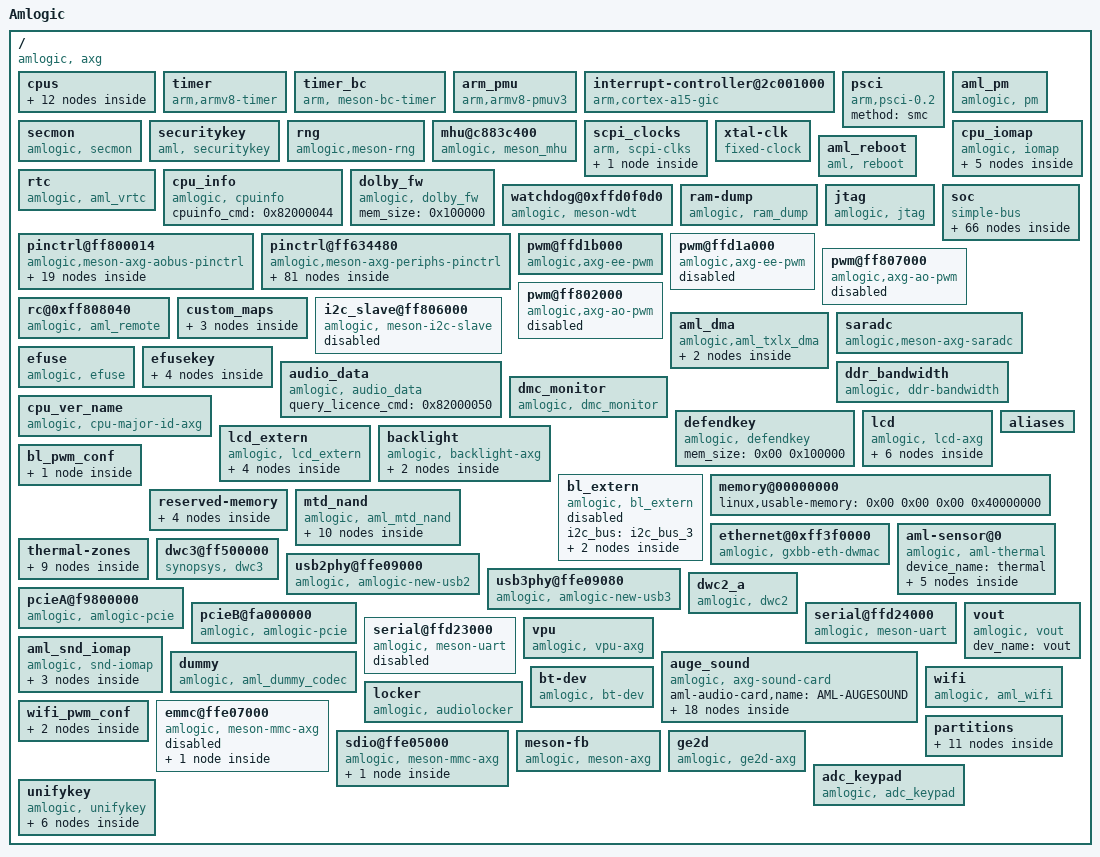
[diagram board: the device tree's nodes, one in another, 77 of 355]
/dts-v1/;

/ {
	model = "Amlogic";
	amlogic-dt-id = "axg_s400_1g";
	compatible = "amlogic, axg";
	interrupt-parent = <0x01>;
	#address-cells = <0x02>;
	#size-cells = <0x02>;

	cpus {
		#address-cells = <0x02>;
		#size-cells = <0x00>;
		phandle = <0x63>;

		cpu-map {

			cluster0 {
				phandle = <0x64>;

				core0 {
					cpu = <0x02>;
				};

				core1 {
					cpu = <0x03>;
				};

				core2 {
					cpu = <0x04>;
				};

				core3 {
					cpu = <0x05>;
				};
			};
		};

		cpu@0 {
			device_type = "cpu";
			compatible = "arm,cortex-a53\0arm,armv8";
			reg = <0x00 0x00>;
			enable-method = "psci";
			clocks = <0x06 0x00>;
			clock-names = "cpu-cluster.0";
			cpu-idle-states = <0x07>;
			phandle = <0x02>;
		};

		cpu@1 {
			device_type = "cpu";
			compatible = "arm,cortex-a53\0arm,armv8";
			reg = <0x00 0x01>;
			enable-method = "psci";
			clocks = <0x06 0x00>;
			clock-names = "cpu-cluster.0";
			cpu-idle-states = <0x07>;
			phandle = <0x03>;
		};

		cpu@2 {
			device_type = "cpu";
			compatible = "arm,cortex-a53\0arm,armv8";
			reg = <0x00 0x02>;
			enable-method = "psci";
			clocks = <0x06 0x00>;
			clock-names = "cpu-cluster.0";
			cpu-idle-states = <0x07>;
			phandle = <0x04>;
		};

		cpu@3 {
			device_type = "cpu";
			compatible = "arm,cortex-a53\0arm,armv8";
			reg = <0x00 0x03>;
			enable-method = "psci";
			clocks = <0x06 0x00>;
			clock-names = "cpu-cluster.0";
			cpu-idle-states = <0x07>;
			phandle = <0x05>;
		};

		idle-states {
			entry-method = "arm,psci-0.2";

			cpu-sleep-0 {
				compatible = "arm,idle-state";
				arm,psci-suspend-param = <0x10000>;
				local-timer-stop;
				entry-latency-us = <0x1388>;
				exit-latency-us = <0x1388>;
				min-residency-us = <0x3a98>;
				phandle = <0x07>;
			};
		};
	};

	timer {
		compatible = "arm,armv8-timer";
		interrupts = <0x01 0x0d 0xff08 0x01 0x0e 0xff08 0x01 0x0b 0xff08 0x01 0x0a 0xff08>;
	};

	timer_bc {
		compatible = "arm, meson-bc-timer";
		reg = <0x00 0xffd0f190 0x00 0x04 0x00 0xffd0f194 0x00 0x04>;
		timer_name = "Meson TimerF";
		clockevent-rating = <0x12c>;
		clockevent-shift = <0x14>;
		clockevent-features = <0x23>;
		interrupts = <0x00 0x3c 0x01>;
		bit_enable = <0x10>;
		bit_mode = <0x0c>;
		bit_resolution = <0x00>;
	};

	arm_pmu {
		compatible = "arm,armv8-pmuv3";
		interrupts = <0x00 0x89 0x04>;
		reg = <0x00 0xff634680 0x00 0x04>;
		cpumasks = <0x0f>;
		relax-timer-ns = <0x989680>;
		max-wait-cnt = <0x2710>;
	};

	interrupt-controller@2c001000 {
		compatible = "arm,cortex-a15-gic\0arm,cortex-a9-gic";
		#interrupt-cells = <0x03>;
		#address-cells = <0x00>;
		interrupt-controller;
		reg = <0x00 0xffc01000 0x00 0x1000 0x00 0xffc02000 0x00 0x100>;
		interrupts = <0x01 0x09 0xf04>;
		phandle = <0x01>;
	};

	psci {
		compatible = "arm,psci-0.2";
		method = "smc";
	};

	aml_pm {
		compatible = "amlogic, pm";
		device_name = "aml_pm";
		status = "okay";
		debug_reg = <0xff8000a8>;
		exit_reg = <0xff80023c>;
	};

	secmon {
		compatible = "amlogic, secmon";
		memory-region = <0x08>;
		in_base_func = <0x82000020>;
		out_base_func = <0x82000021>;
		reserve_mem_size = <0x300000>;
	};

	securitykey {
		compatible = "aml, securitykey";
		storage_query = <0x82000060>;
		storage_read = <0x82000061>;
		storage_write = <0x82000062>;
		storage_tell = <0x82000063>;
		storage_verify = <0x82000064>;
		storage_status = <0x82000065>;
		storage_list = <0x82000067>;
		storage_remove = <0x82000068>;
		storage_in_func = <0x82000023>;
		storage_out_func = <0x82000024>;
		storage_block_func = <0x82000025>;
		storage_size_func = <0x82000027>;
		storage_set_enctype = <0x8200006a>;
		storage_get_enctype = <0x8200006b>;
		storage_version = <0x8200006c>;
	};

	rng {
		compatible = "amlogic,meson-rng";
		status = "okay";
		#address-cells = <0x02>;
		#size-cells = <0x02>;
		reg = <0x00 0xff634018 0x00 0x04>;
		quality = [03 e8];
	};

	mhu@c883c400 {
		compatible = "amlogic, meson_mhu";
		reg = <0x00 0xff63c400 0x00 0x4c 0x00 0xfffd3000 0x00 0x800>;
		interrupts = <0x00 0xd1 0x01 0x00 0xd2 0x01>;
		#mbox-cells = <0x01>;
		mbox-names = "cpu_to_scp_low\0cpu_to_scp_high";
		mboxes = <0x09 0x00 0x09 0x01>;
		phandle = <0x09>;
	};

	scpi_clocks {
		compatible = "arm, scpi-clks";

		scpi_clocks@0 {
			compatible = "arm, scpi-clk-indexed";
			#clock-cells = <0x01>;
			clock-indices = <0x00>;
			clock-output-names = "vcpu";
			phandle = <0x06>;
		};
	};

	cpu_iomap {
		compatible = "amlogic, iomap";
		#address-cells = <0x02>;
		#size-cells = <0x02>;
		ranges;

		io_cbus_base {
			reg = <0x00 0xffd00000 0x00 0x100000>;
		};

		io_apb_base {
			reg = <0x00 0xffe00000 0x00 0x100000>;
		};

		io_aobus_base {
			reg = <0x00 0xff800000 0x00 0x100000>;
		};

		io_vapb_base {
			reg = <0x00 0xff900000 0x00 0x50000>;
		};

		io_hiu_base {
			reg = <0x00 0xff63c000 0x00 0x10000>;
		};
	};

	xtal-clk {
		compatible = "fixed-clock";
		clock-frequency = <0x16e3600>;
		clock-output-names = "xtal";
		#clock-cells = <0x00>;
		phandle = <0x0a>;
	};

	rtc {
		compatible = "amlogic, aml_vrtc";
		alarm_reg_addr = <0xff8000a8>;
		timer_e_addr = <0xffd0f188>;
		init_date = "2015/01/01";
		status = "okay";
	};

	cpu_info {
		compatible = "amlogic, cpuinfo";
		status = "okay";
		cpuinfo_cmd = <0x82000044>;
	};

	aml_reboot {
		compatible = "aml, reboot";
		sys_reset = <0x84000009>;
		sys_poweroff = <0x84000008>;
	};

	dolby_fw {
		compatible = "amlogic, dolby_fw";
		mem_size = <0x100000>;
		status = "okay";
		phandle = <0x65>;
	};

	watchdog@0xffd0f0d0 {
		compatible = "amlogic, meson-wdt";
		status = "okay";
		default_timeout = <0x0a>;
		reset_watchdog_method = <0x01>;
		reset_watchdog_time = <0x02>;
		shutdown_timeout = <0x0a>;
		firmware_timeout = <0x06>;
		suspend_timeout = <0x06>;
		reg = <0x00 0xffd0f0d0 0x00 0x10>;
		clock-names = "xtal";
		clocks = <0x0a>;
		phandle = <0x66>;
	};

	ram-dump {
		compatible = "amlogic, ram_dump";
		status = "okay";
		reg = <0x00 0xff6345e0 0x00 0x04>;
		reg-names = "PREG_STICKY_REG8";
		store_device = "data";
	};

	jtag {
		compatible = "amlogic, jtag";
		status = "okay";
		select = "disable";
		pinctrl-names = "jtag_apao_pins\0jtag_apee_pins";
		pinctrl-0 = <0x0b>;
		pinctrl-1 = <0x0c>;
	};

	pinctrl@ff800014 {
		compatible = "amlogic,meson-axg-aobus-pinctrl";
		#address-cells = <0x02>;
		#size-cells = <0x02>;
		ranges;
		phandle = <0x67>;

		ao-bank@ff800014 {
			reg = <0x00 0xff800014 0x00 0x08 0x00 0xff80002c 0x00 0x04 0x00 0xff800024 0x00 0x08>;
			reg-names = "mux\0pull\0gpio";
			gpio-controller;
			#gpio-cells = <0x02>;
			phandle = <0x0f>;
		};

		remote_pin {
			phandle = <0x21>;

			mux {
				groups = "remote_input_ao";
				function = "remote_input_ao";
			};
		};

		irblaster_pin {
			phandle = <0x11>;

			mux {
				groups = "remote_out_ao";
				function = "remote_out_ao";
			};
		};

		ao_uart {
			phandle = <0x12>;

			mux {
				groups = "uart_ao_tx_a\0uart_ao_rx_a";
				function = "uart_ao_a";
			};
		};

		ao_b_1_uart {
			phandle = <0x68>;

			mux {
				groups = "uart_ao_tx_b\0uart_ao_rx_b";
				function = "uart_ao_b";
			};
		};

		ao_i2c {
			phandle = <0x69>;

			mux {
				groups = "i2c_ao_sck_4\0i2c_ao_sda_5";
				function = "i2c_ao";
			};
		};

		ao_i2c_pin1 {
			phandle = <0x6a>;

			mux {
				groups = "i2c_ao_sck_8\0i2c_ao_sda_9";
				function = "i2c_ao";
			};
		};

		ao_i2c_pin2 {
			phandle = <0x10>;

			mux {
				groups = "i2c_ao_sck_10\0i2c_ao_sda_11";
				function = "i2c_ao";
			};
		};

		s_i2c {
			phandle = <0x26>;

			mux {
				groups = "i2c_ao_slave_sck\0i2c_ao_slave_sda";
				function = "i2c_ao_slave";
			};
		};

		jtag_apao_pin {
			phandle = <0x0b>;

			mux {
				groups = "jtag_ao_tdi\0jtag_ao_tdo\0jtag_ao_clk\0jtag_ao_tms";
				function = "jtag_ao";
			};
		};
	};

	pinctrl@ff634480 {
		compatible = "amlogic,meson-axg-periphs-pinctrl";
		#address-cells = <0x02>;
		#size-cells = <0x02>;
		ranges;
		phandle = <0x6b>;

		banks@ff634480 {
			reg = <0x00 0xff634480 0x00 0x40 0x00 0xff6344e8 0x00 0x14 0x00 0xff634520 0x00 0x14 0x00 0xff634430 0x00 0x3c>;
			reg-names = "mux\0pull\0pull-enable\0gpio";
			gpio-controller;
			#gpio-cells = <0x02>;
			phandle = <0x2c>;
		};

		external_eth_pins {
			phandle = <0x36>;

			mux {
				groups = "eth_mdio_y\0eth_mdc_y\0eth_rgmii_rx_clk_y\0eth_rx_dv_y\0eth_rxd0_y\0eth_rxd1_y\0eth_rxd2_rgmii\0eth_rxd3_rgmii\0eth_rgmii_tx_clk\0eth_txen_y\0eth_txd0_y\0eth_txd1_y\0eth_txd2_rgmii\0eth_txd3_rgmii";
				function = "eth";
			};
		};

		ao_b_uart {
			phandle = <0x13>;

			mux {
				groups = "uart_ao_tx_b_z\0uart_ao_rx_b_z";
				function = "uart_ao_b";
			};
		};

		a_uart {
			phandle = <0x3d>;

			mux {
				groups = "uart_tx_a\0uart_rx_a\0uart_cts_a\0uart_rts_a";
				function = "uart_a";
			};
		};

		b_uart {
			phandle = <0x3e>;

			mux {
				groups = "uart_tx_b_z\0uart_rx_b_z";
				function = "uart_b";
			};
		};

		a_i2c {
			phandle = <0x6c>;

			mux {
				groups = "i2c0_sck\0i2c0_sda";
				function = "i2c0";
			};
		};

		b_i2c {
			phandle = <0x0e>;

			mux {
				groups = "i2c1_sck_z\0i2c1_sda_z";
				function = "i2c1";
			};
		};

		b_i2c_pin1 {
			phandle = <0x6d>;

			mux {
				groups = "i2c1_sck_x\0i2c1_sda_x";
				function = "i2c1";
			};
		};

		c_i2c {
			phandle = <0x6e>;

			mux {
				groups = "i2c2_sck_x\0i2c2_sda_x";
				function = "i2c2";
			};
		};

		c_i2c_pin1 {
			phandle = <0x6f>;

			mux {
				groups = "i2c2_sck_a\0i2c2_sda_a";
				function = "i2c2";
			};
		};

		d_i2c {
			phandle = <0x70>;

			mux {
				groups = "i2c3_sda_a6\0i2c3_sck_a7";
				function = "i2c3";
			};
		};

		d_i2c_pin1 {
			phandle = <0x71>;

			mux {
				groups = "i2c3_sda_a12\0i2c3_sck_a13";
				function = "i2c3";
			};
		};

		d_i2c_pin2 {
			phandle = <0x72>;

			mux {
				groups = "i2c3_sda_a19\0i2c3_sck_a20";
				function = "i2c3";
			};
		};

		spi0 {
			phandle = <0x73>;

			mux {
				groups = "spi0_clk\0spi0_mosi\0spi0_miso";
				function = "spi0";
			};
		};

		spi1_a {
			phandle = <0x74>;

			mux {
				groups = "spi1_clk_a\0spi1_mosi_a\0spi1_miso_a";
				function = "spi1";
			};
		};

		spi1_x {
			phandle = <0x75>;

			mux {
				groups = "spi1_clk_x\0spi1_mosi_x\0spi1_miso_x";
				function = "spi1";
			};
		};

		nand_pulldown {
			phandle = <0x76>;

			mux {
				groups = "emmc_nand_d0\0emmc_nand_d1\0emmc_nand_d2\0emmc_nand_d3\0emmc_nand_d4\0emmc_nand_d5\0emmc_nand_d6\0emmc_nand_d7";
				function = "nand";
				bias-pull-down;
			};
		};

		nand_pullup {
			phandle = <0x77>;

			mux {
				groups = "nand_ce0";
				function = "nand";
				bias-pull-up;
			};
		};

		all_nand_pins {
			phandle = <0x31>;

			mux {
				groups = "emmc_nand_d0\0emmc_nand_d1\0emmc_nand_d2\0emmc_nand_d3\0emmc_nand_d4\0emmc_nand_d5\0emmc_nand_d6\0emmc_nand_d7\0nand_ce0\0nand_ale\0nand_cle\0nand_wen_clk\0nand_ren_wr";
				function = "nand";
				input-enable;
			};
		};

		nand_cs {
			phandle = <0x32>;

			mux {
				groups = "nand_ce0";
				function = "nand";
			};
		};

		emmc_clk_cmd_pins {
			phandle = <0x4b>;

			mux {
				groups = "emmc_clk\0emmc_cmd";
				function = "emmc";
				input-enable;
				bias-pull-up;
			};
		};

		emmc_conf_pull_up {
			phandle = <0x4c>;

			mux {
				groups = "emmc_nand_d0\0emmc_nand_d1\0emmc_nand_d2\0emmc_nand_d3\0emmc_nand_d4\0emmc_nand_d5\0emmc_nand_d6\0emmc_nand_d7\0emmc_clk\0emmc_cmd";
				function = "emmc";
				input-enable;
				bias-pull-up;
			};
		};

		emmc_conf_pull_done {
			phandle = <0x4d>;

			mux {
				groups = "emmc_ds";
				function = "emmc";
				input-enable;
				bias-pull-down;
			};
		};

		sdio_clk_cmd_pins {
			phandle = <0x4e>;

			mux {
				groups = "sdio_clk\0sdio_cmd";
				function = "sdio";
				input-enable;
				bias-pull-up;
			};
		};

		sdio_all_pins {
			phandle = <0x4f>;

			mux {
				groups = "sdio_d0\0sdio_d1\0sdio_d2\0sdio_d3\0sdio_clk\0sdio_cmd";
				function = "sdio";
				input-enable;
				bias-pull-up;
			};
		};

		wifi_32k_pins {
			phandle = <0x49>;

			mux {
				groups = "pwm_a_x20";
				function = "pwm_a";
			};
		};

		jtag_apee_pin {
			phandle = <0x0c>;

			mux {
				groups = "jtag_tdo_x\0jtag_tdi_x\0jtag_clk_x\0jtag_tms_x";
				function = "jtag_ee";
			};
		};

		tdmout_a {
			phandle = <0x15>;

			mux {
				groups = "tdma_sclk\0tdma_fs";
				function = "tdma_out";
			};
		};

		tdmout_a_data {
			phandle = <0x17>;

			mux {
				groups = "tdma_dout1_x15";
				function = "tdma_out";
			};
		};

		tdmin_a {
			phandle = <0x16>;

			mux {
				groups = "tdma_din0";
				function = "tdma_in";
			};
		};

		tdmb_mclk {
			phandle = <0x18>;

			mux {
				groups = "mclk_b";
				function = "mclk_b";
			};
		};

		tdmout_b {
			phandle = <0x19>;

			mux {
				groups = "tdmb_sclk\0tdmb_fs";
				function = "tdmb_out";
			};
		};

		tdmin_b {
			phandle = <0x1a>;

			mux {
				groups = "tdmb_din0\0tdmb_din1\0tdmb_din2_a12\0tdmb_din3_a13";
				function = "tdmb_in";
			};
		};

		tdmc_mclk {
			phandle = <0x1b>;

			mux {
				groups = "mclk_a";
				function = "mclk_a";
			};
		};

		tdmout_c {
			phandle = <0x1c>;

			mux {
				groups = "tdmc_sclk\0tdmc_fs\0tdmc_dout0\0tdmc_dout2_a6\0tdmc_dout3_a7";
				function = "tdmc_out";
			};
		};

		tdmin_c {
			phandle = <0x1d>;

			mux {
				groups = "tdmc_din1";
				function = "tdmc_in";
			};
		};

		spidfout {
			phandle = <0x1e>;

			mux {
				groups = "spdif_out_a20";
				function = "spdif_out";
			};
		};

		spidfin {
			phandle = <0x1f>;

			mux {
				groups = "spdif_in_a19";
				function = "spdif_in";
			};
		};

		pdmin {
			phandle = <0x20>;

			mux {
				groups = "pdm_dclk_a14\0pdm_din0\0pdm_din1\0pdm_din2\0pdm_din3";
				function = "pdm";
			};
		};

		bl_pwm_on_pin {
			phandle = <0x2d>;

			mux {
				groups = "pwm_b_z";
				function = "pwm_b";
			};
		};

		bl_pwm_off_pin {
			phandle = <0x2e>;

			mux {
				pins = "GPIOZ_4";
				function = "gpio_periphs";
				output-high;
			};
		};
	};

	soc {
		compatible = "simple-bus";
		#address-cells = <0x02>;
		#size-cells = <0x02>;
		ranges;

		cbus@ffd00000 {
			compatible = "simple-bus";
			reg = <0x00 0xffd00000 0x00 0x25000>;
			#address-cells = <0x02>;
			#size-cells = <0x02>;
			ranges = <0x00 0x00 0x00 0xffd00000 0x00 0x25000>;
			phandle = <0x78>;

			interrupt-controller@f080 {
				compatible = "amlogic,meson-gpio-intc\0amlogic,meson-axg-gpio-intc";
				reg = <0x00 0xf080 0x00 0x10>;
				interrupt-controller;
				#interrupt-cells = <0x02>;
				amlogic,channel-interrupts = <0x40 0x41 0x42 0x43 0x44 0x45 0x46 0x47>;
				status = "okay";
				phandle = <0x79>;
			};

			meson_clk_msr {
				compatible = "amlogic, gxl_measure";
				reg = <0x00 0x18004 0x00 0x04 0x00 0x1800c 0x00 0x04>;
			};

			i2c@1f000 {
				compatible = "amlogic,meson-axg-i2c";
				status = "disabled";
				reg = <0x00 0x1f000 0x00 0x20>;
				interrupts = <0x00 0x15 0x01 0x00 0x2f 0x01>;
				#address-cells = <0x01>;
				#size-cells = <0x00>;
				clocks = <0x0d 0x27>;
				clock-names = "clk_i2c";
				clock-frequency = <0x186a0>;
				phandle = <0x7a>;
			};

			i2c@1e000 {
				compatible = "amlogic,meson-axg-i2c";
				status = "okay";
				reg = <0x00 0x1e000 0x00 0x20>;
				interrupts = <0x00 0xd6 0x01 0x00 0x30 0x01>;
				#address-cells = <0x01>;
				#size-cells = <0x00>;
				clocks = <0x0d 0x27>;
				clock-names = "clk_i2c";
				clock-frequency = <0x186a0>;
				pinctrl-names = "default";
				pinctrl-0 = <0x0e>;
				phandle = <0x7b>;

				tlv320adc3101_32@32 {
					compatible = "ti,tlv320adc3101";
					#sound-dai-cells = <0x00>;
					reg = <0x19>;
					differential_pair = <0x01>;
					status = "okay";
					phandle = <0x42>;
				};

				tas5707_36@36 {
					compatible = "ti,tas5707";
					#sound-dai-cells = <0x00>;
					reg = <0x1b>;
					status = "okay";
					reset_pin = <0x0f 0x04 0x00>;
					phandle = <0x44>;
				};

				tas5707_3a@3a {
					compatible = "ti,tas5707";
					#sound-dai-cells = <0x00>;
					reg = <0x1d>;
					status = "okay";
					phandle = <0x45>;
				};
			};

			i2c@1d000 {
				compatible = "amlogic,meson-axg-i2c";
				status = "disabled";
				reg = <0x00 0x1d000 0x00 0x20>;
				interrupts = <0x00 0xd7 0x01 0x00 0x31 0x01>;
				#address-cells = <0x01>;
				#size-cells = <0x00>;
				clocks = <0x0d 0x27>;
				clock-names = "clk_i2c";
				clock-frequency = <0x186a0>;
				phandle = <0x7c>;
			};

			i2c@1c000 {
				compatible = "amlogic,meson-axg-i2c";
				status = "disabled";
				reg = <0x00 0x1c000 0x00 0x20>;
				interrupts = <0x00 0x27 0x01 0x00 0x32 0x01>;
				#address-cells = <0x01>;
				#size-cells = <0x00>;
				clocks = <0x0d 0x27>;
				clock-names = "clk_i2c";
				clock-frequency = <0x186a0>;
				phandle = <0x7d>;
			};

			spi@13000 {
				compatible = "amlogic,meson-axg-spicc";
				reg = <0x00 0x13000 0x00 0x40>;
				interrupts = <0x00 0x51 0x04>;
				clocks = <0x0d 0x26 0x0d 0x76>;
				clock-names = "core\0comp";
				#address-cells = <0x01>;
				#size-cells = <0x00>;
				status = "disabled";
				phandle = <0x7e>;
			};

			spi@15000 {
				compatible = "amlogic,meson-axg-spicc";
				reg = <0x00 0x15000 0x00 0x40>;
				interrupts = <0x00 0x52 0x04>;
				clocks = <0x0d 0x2b 0x0d 0x76>;
				clock-names = "core\0comp";
				#address-cells = <0x01>;
				#size-cells = <0x00>;
				status = "disabled";
				phandle = <0x7f>;
			};
		};

		aobus@ff800000 {
			compatible = "simple-bus";
			reg = <0x00 0xff800000 0x00 0xa000>;
			#address-cells = <0x02>;
			#size-cells = <0x02>;
			ranges = <0x00 0x00 0x00 0xff800000 0x00 0xa000>;
			phandle = <0x80>;

			cpu_version {
				reg = <0x00 0x220 0x00 0x04>;
			};

			clock-controller@0 {
				compatible = "amlogic,axg-aoclkc";
				#clock-cells = <0x01>;
				reg = <0x00 0x00 0x00 0x320>;
				phandle = <0x81>;
			};

			i2c@5000 {
				compatible = "amlogic,meson-axg-i2c";
				status = "okay";
				reg = <0x00 0x5000 0x00 0x20>;
				interrupts = <0x00 0xc3 0x01>;
				#address-cells = <0x01>;
				#size-cells = <0x00>;
				clocks = <0x0d 0x27>;
				clock-names = "clk_i2c";
				clock-frequency = <0x186a0>;
				pinctrl-names = "default";
				pinctrl-0 = <0x10>;
				phandle = <0x82>;

				aml_pca9557@0x1f {
					compatible = "aml, ledring";
					reg = <0x1f>;
					mode = <0x00>;
					key_num = <0x04>;
					led_dev_name = "aml_ledring";
					key_dev_name = "aml_pca_key";
					key_name = "mute\0pause\0vol+\0vol-";
					key_value = <0xc8 0xc9 0xca 0xcb>;
					status = "okay";
					phandle = <0x83>;
				};

				tlv320adc3101_30@30 {
					compatible = "ti,tlv320adc3101";
					#sound-dai-cells = <0x00>;
					reg = <0x18>;
					status = "disable";
					phandle = <0x84>;
				};

				tlv320adc3101_34@30 {
					compatible = "ti,tlv320adc3101";
					#sound-dai-cells = <0x00>;
					reg = <0x1a>;
					status = "disable";
					phandle = <0x85>;
				};

				tlv320adc3101_36@30 {
					compatible = "ti,tlv320adc3101";
					#sound-dai-cells = <0x00>;
					reg = <0x1b>;
					status = "disable";
					phandle = <0x86>;
				};

				es7243_10@10 {
					compatible = "MicArray_0";
					#sound-dai-cells = <0x00>;
					reg = <0x10>;
					status = "disable";
					phandle = <0x87>;
				};

				es7243_12@12 {
					compatible = "MicArray_1";
					#sound-dai-cells = <0x00>;
					reg = <0x12>;
					status = "disable";
					phandle = <0x88>;
				};

				es7243_13@13 {
					compatible = "MicArray_2";
					#sound-dai-cells = <0x00>;
					reg = <0x13>;
					status = "disable";
					phandle = <0x89>;
				};

				is31f3236a@0x78 {
					compatible = "issi,is31fl3236";
					reg = <0x3c>;
					status = "disable";
					phandle = <0x8a>;

					led1_r {
						label = "LED1_R";
						reg_offset = <0x18>;
					};

					led1_g {
						label = "LED1_G";
						reg_offset = <0x17>;
					};

					led1_b {
						label = "LED1_B";
						reg_offset = <0x16>;
					};

					led2_r {
						label = "LED2_R";
						reg_offset = <0x15>;
					};

					led2_g {
						label = "LED2_G";
						reg_offset = <0x14>;
					};

					led2_b {
						label = "LED2_B";
						reg_offset = <0x13>;
					};

					led3_r {
						label = "LED3_R";
						reg_offset = <0x12>;
					};

					led3_g {
						label = "LED3_G";
						reg_offset = <0x11>;
					};

					led3_b {
						label = "LED3_B";
						reg_offset = <0x10>;
					};

					led4_r {
						label = "LED4_R";
						reg_offset = <0x0f>;
					};

					led4_g {
						label = "LED4_G";
						reg_offset = <0x0e>;
					};

					led4_b {
						label = "LED4_B";
						reg_offset = <0x0d>;
					};

					led5_r {
						label = "LED5_R";
						reg_offset = <0x24>;
					};

					led5_g {
						label = "LED5_G";
						reg_offset = <0x23>;
					};

					led5_b {
						label = "LED5_B";
						reg_offset = <0x22>;
					};

					led6_r {
						label = "LED6_R";
						reg_offset = <0x21>;
					};

					led6_g {
						label = "LED6_G";
						reg_offset = <0x20>;
					};

					led6_b {
						label = "LED6_B";
						reg_offset = <0x1f>;
					};

					led7_r {
						label = "LED7_R";
						reg_offset = <0x1e>;
					};

					led7_g {
						label = "LED7_G";
						reg_offset = <0x1d>;
					};

					led7_b {
						label = "LED7_B";
						reg_offset = <0x1c>;
					};

					led8_r {
						label = "LED8_R";
						reg_offset = <0x1b>;
					};

					led8_g {
						label = "LED8_G";
						reg_offset = <0x1a>;
					};

					led8_b {
						label = "LED8_B";
						reg_offset = <0x19>;
					};
				};
			};

			meson-irblaster@c0 {
				compatible = "amlogic, aml_irblaster";
				reg = <0x00 0xc0 0x00 0x0c 0x00 0x40 0x00 0x04>;
				#irblaster-cells = <0x02>;
				pinctrl-names = "default";
				pinctrl-0 = <0x11>;
				status = "disabled";
				phandle = <0x8b>;
			};

			serial@3000 {
				compatible = "amlogic, meson-uart";
				reg = <0x00 0x3000 0x00 0x18>;
				interrupts = <0x00 0xc1 0x01>;
				status = "okay";
				clocks = <0x0a>;
				clock-names = "clk_uart";
				xtal_tick_en = <0x01>;
				fifosize = <0x40>;
				pinctrl-names = "default";
				pinctrl-0 = <0x12>;
				support-sysrq = <0x00>;
				phandle = <0x8c>;
			};

			serial@4000 {
				compatible = "amlogic, meson-uart";
				reg = <0x00 0x4000 0x00 0x18>;
				interrupts = <0x00 0xc5 0x01>;
				status = "disable";
				clocks = <0x0a>;
				clock-names = "clk_uart";
				fifosize = <0x40>;
				pinctrl-names = "default";
				pinctrl-0 = <0x13>;
				phandle = <0x8d>;
			};
		};

		periphs@ff634400 {
			compatible = "simple-bus";
			reg = <0x00 0xff634400 0x00 0x1c00>;
			#address-cells = <0x02>;
			#size-cells = <0x02>;
			ranges = <0x00 0x00 0x00 0xff634400 0x00 0x1c00>;
			phandle = <0x8e>;
		};

		hiubus@ff63c000 {
			compatible = "simple-bus";
			reg = <0x00 0xff63c000 0x00 0x10000>;
			#address-cells = <0x02>;
			#size-cells = <0x02>;
			ranges = <0x00 0x00 0x00 0xff63c000 0x00 0x10000>;
			phandle = <0x8f>;

			clock-controller@0 {
				compatible = "amlogic,axg-clkc";
				#clock-cells = <0x01>;
				reg = <0x00 0x00 0x00 0x320>;
				phandle = <0x0d>;
			};
		};

		audiobus@0xff642000 {
			compatible = "amlogic, audio-controller\0simple-bus";
			reg = <0x00 0xff642000 0x00 0x2000>;
			#address-cells = <0x02>;
			#size-cells = <0x02>;
			ranges = <0x00 0x00 0x00 0xff642000 0x00 0x2000>;
			phandle = <0x90>;

			audio_clocks {
				compatible = "amlogic, axg-audio-clocks";
				#clock-cells = <0x01>;
				reg = <0x00 0x00 0x00 0xb0>;
				phandle = <0x14>;
			};

			ddr_manager {
				compatible = "amlogic, axg-audio-ddr-manager";
				interrupts = <0x00 0x54 0x01 0x00 0x55 0x01 0x00 0x56 0x01 0x00 0x58 0x01 0x00 0x59 0x01 0x00 0x5a 0x01>;
				interrupt-names = "toddr_a\0toddr_b\0toddr_c\0frddr_a\0frddr_b\0frddr_c";
			};

			tdma {
				compatible = "amlogic, axg-snd-tdma";
				#sound-dai-cells = <0x00>;
				dai-tdm-lane-slot-mask-in = <0x01 0x00>;
				dai-tdm-lane-slot-mask-out = <0x00 0x01>;
				dai-tdm-clk-sel = <0x00>;
				clocks = <0x14 0x14 0x0d 0x0c>;
				clock-names = "mclk\0clk_srcpll";
				pinctrl-names = "tdm_pins";
				pinctrl-0 = <0x15 0x16 0x17>;
				phandle = <0x3f>;
			};

			tdmb {
				compatible = "amlogic, axg-snd-tdmb";
				#sound-dai-cells = <0x00>;
				dai-tdm-lane-slot-mask-in = <0x01 0x01 0x01 0x01>;
				dai-tdm-clk-sel = <0x01>;
				clocks = <0x14 0x15 0x0d 0x0d>;
				clock-names = "mclk\0clk_srcpll";
				pinctrl-names = "tdm_pins";
				pinctrl-0 = <0x18 0x19 0x1a>;
				phandle = <0x41>;
			};

			tdmc {
				compatible = "amlogic, axg-snd-tdmc";
				#sound-dai-cells = <0x00>;
				dai-tdm-lane-slot-mask-in = <0x00 0x01 0x00 0x00>;
				dai-tdm-lane-slot-mask-out = <0x01 0x00 0x01 0x01>;
				#dai-tdm-lane-oe-slot-mask-in = <0x00 0x00 0x00 0x00>;
				#dai-tdm-lane-oe-slot-mask-out = <0x01 0x00 0x00 0x00>;
				dai-tdm-clk-sel = <0x02>;
				clocks = <0x14 0x16 0x0d 0x0e>;
				clock-names = "mclk\0clk_srcpll";
				pinctrl-names = "tdm_pins";
				pinctrl-0 = <0x1b 0x1c 0x1d>;
				phandle = <0x43>;
			};

			tdm@3 {
				compatible = "amlogic, axg-snd-tdmlb";
				#sound-dai-cells = <0x00>;
				dai-tdm-lane-lb-slot-mask-in = <0x01 0x00 0x00 0x00>;
				dai-tdm-clk-sel = <0x01>;
				clocks = <0x14 0x15 0x0d 0x0d>;
				clock-names = "mclk\0clk_srcpll";
				lb-src-sel = <0x01>;
				status = "disabled";
				phandle = <0x91>;
			};

			spdif {
				compatible = "amlogic, axg-snd-spdif";
				#sound-dai-cells = <0x00>;
				clocks = <0x0d 0x0c 0x0d 0x04 0x14 0x10 0x14 0x11 0x14 0x1a 0x14 0x1b>;
				clock-names = "sysclk\0fixed_clk\0gate_spdifin\0gate_spdifout\0clk_spdifin\0clk_spdifout";
				interrupts = <0x00 0x57 0x01>;
				interrupt-names = "irq_spdifin";
				pinctrl-names = "spdif_pins";
				pinctrl-0 = <0x1e 0x1f>;
				auto_asrc = <0x00>;
				status = "okay";
				phandle = <0x47>;
			};

			pdm {
				compatible = "amlogic, axg-snd-pdm";
				#sound-dai-cells = <0x00>;
				clocks = <0x14 0x01 0x0d 0x03 0x0d 0x0f 0x14 0x1c 0x14 0x1d>;
				clock-names = "gate\0sysclk_srcpll\0dclk_srcpll\0pdm_dclk\0pdm_sysclk";
				pinctrl-names = "pdm_pins";
				pinctrl-0 = <0x20>;
				filter_mode = <0x01>;
				status = "okay";
				phandle = <0x46>;
			};

			loopback@0 {
				compatible = "amlogic, axg-loopback";
				#sound-dai-cells = <0x00>;
				clocks = <0x14 0x01 0x0d 0x03 0x0d 0x0f 0x14 0x1c 0x14 0x1d 0x0d 0x0c 0x14 0x14>;
				clock-names = "pdm_gate\0pdm_sysclk_srcpll\0pdm_dclk_srcpll\0pdm_dclk\0pdm_sysclk\0tdminlb_mpll\0tdminlb_mclk";
				datain_src = <0x04>;
				datain_chnum = <0x06>;
				datain_chmask = <0x3f>;
				datain-lane-mask-in = <0x01 0x01 0x01 0x00>;
				mclk-fs = <0x100>;
				datalb_src = <0x02>;
				datalb_chnum = <0x02>;
				datalb_chmask = <0x03>;
				datalb-lane-mask-in = <0x01 0x00 0x00 0x00>;
				status = "okay";
				phandle = <0x48>;
			};

			resample {
				compatible = "amlogic, axg-resample";
				clocks = <0x0d 0x0f 0x14 0x19 0x14 0x20>;
				clock-names = "resample_pll\0resample_src\0resample_clk";
				resample_module = <0x03>;
				status = "okay";
				phandle = <0x92>;
			};

			pwrdet {
				compatible = "amlogic, axg-power-detect";
				interrupts = <0x00 0x5b 0x01>;
				interrupt-names = "pwrdet_irq";
				pwrdet_src = <0x04>;
				hi_th = <0x70000>;
				lo_th = <0x16000>;
				status = "disabled";
				phandle = <0x93>;
			};
		};
	};

	pwm@ffd1b000 {
		compatible = "amlogic,axg-ee-pwm";
		reg = <0x00 0xffd1b000 0x00 0x20>;
		#pwm-cells = <0x03>;
		clocks = <0x0a 0x0a 0x0a 0x0a>;
		clock-names = "clkin0\0clkin1\0clkin2\0clkin3";
		status = "okay";
		phandle = <0x30>;
	};

	pwm@ffd1a000 {
		compatible = "amlogic,axg-ee-pwm";
		reg = <0x00 0xffd1a000 0x00 0x20>;
		#pwm-cells = <0x03>;
		clocks = <0x0a 0x0a 0x0a 0x0a>;
		clock-names = "clkin0\0clkin1\0clkin2\0clkin3";
		status = "disabled";
		phandle = <0x94>;
	};

	pwm@ff807000 {
		compatible = "amlogic,axg-ao-pwm";
		reg = <0x00 0xff807000 0x00 0x20>;
		#pwm-cells = <0x03>;
		clocks = <0x0a 0x0a 0x0a 0x0a>;
		clock-names = "clkin0\0clkin1\0clkin2\0clkin3";
		status = "disabled";
		phandle = <0x95>;
	};

	pwm@ff802000 {
		compatible = "amlogic,axg-ao-pwm";
		reg = <0x00 0xff802000 0x00 0x20>;
		#pwm-cells = <0x03>;
		clocks = <0x0a 0x0a 0x0a 0x0a>;
		clock-names = "clkin0\0clkin1\0clkin2\0clkin3";
		status = "disabled";
		phandle = <0x96>;
	};

	rc@0xff808040 {
		compatible = "amlogic, aml_remote";
		dev_name = "meson-remote";
		reg = <0x00 0xff808040 0x00 0x44 0x00 0xff808000 0x00 0x20>;
		status = "okay";
		protocol = <0x01>;
		interrupts = <0x00 0xc4 0x01>;
		pinctrl-names = "default";
		pinctrl-0 = <0x21>;
		map = <0x22>;
		max_frame_time = <0xc8>;
		phandle = <0x97>;
	};

	custom_maps {
		mapnum = <0x03>;
		map0 = <0x23>;
		map1 = <0x24>;
		map2 = <0x25>;
		phandle = <0x22>;

		map_0 {
			mapname = "amlogic-remote-1";
			customcode = <0xfb04>;
			release_delay = <0x50>;
			size = <0x32>;
			keymap = <0x47000b 0x130002 0x100003 0x110004 0xf0005 0xc0006 0xd0007 0xb0008 0x80009 0x9000a 0x5c0061 0x51003d 0x50003e 0x40003f 0x4d0040 0x430041 0x170042 0x43 0x10044 0x160057 0x49000e 0x60082 0x140083 0x440067 0x1d006c 0x1c0069 0x48006a 0x53007d 0x450068 0x19006d 0x520077 0x5007a 0x59007b 0x1b0078 0x40079 0x1a0074 0xa000f 0xe0071 0x1f0066 0x1e0084 0x70085 0x120086 0x540087 0x20088 0x4f001e 0x420030 0x5d002e 0x4c0020 0x580089 0x55008c>;
			phandle = <0x23>;
		};

		map_1 {
			mapname = "amlogic-remote-2";
			customcode = <0xfe01>;
			release_delay = <0x50>;
			size = <0x35>;
			keymap = <0x10002 0x20003 0x30004 0x40005 0x50006 0x60007 0x70008 0x80009 0x9000a 0xa000b 0x1f01d2 0x15008b 0x16000f 0xc0192 0xd0193 0xe0073 0xf0072 0x110066 0x1c006a 0x1b0069 0x190067 0x1a006c 0x1d001c 0x170071 0x4900db 0x43009e 0x1201d5 0x1401d6 0x1801d7 0x590166 0x5a00a6 0x100074 0x4200a5 0x4400a3 0x1e00a8 0x4b00d0 0x5800a4 0x460082 0x400083 0x380046 0x5701d0 0x5b01d1 0x54018e 0x4c018f 0x4e0190 0x550191 0x5300ed 0x5200ee 0x3900d4 0x4100d5 0xb00d6 0xd8 0x1300d9>;
			phandle = <0x24>;
		};

		map_2 {
			mapname = "amlogic-remote-3";
			customcode = <0xbd02>;
			release_delay = <0x50>;
			size = <0x11>;
			keymap = <0xca0067 0xd2006c 0x990069 0xc1006a 0xce0061 0x450074 0xc50085 0x800071 0xd0000f 0xd6007d 0x950066 0xdd0068 0x8c006d 0x890083 0x9c0082 0x9a0078 0xcd0079>;
			phandle = <0x25>;
		};
	};

	i2c_slave@ff806000 {
		compatible = "amlogic, meson-i2c-slave";
		status = "disabled";
		reg = <0x00 0xff806000 0x00 0x20>;
		interrupts = <0x00 0xc2 0x01>;
		pinctrl-names = "default";
		pinctrl-0 = <0x26>;
		phandle = <0x98>;
	};

	aml_dma {
		compatible = "amlogic,aml_txlx_dma";
		reg = <0x00 0xff63e000 0x00 0x48>;
		interrupts = <0x00 0xb4 0x01>;

		aml_aes {
			compatible = "amlogic,aes_dma";
			dev_name = "aml_aes_dma";
			status = "okay";
		};

		aml_sha {
			compatible = "amlogic,sha_dma";
			dev_name = "aml_sha_dma";
			status = "okay";
		};
	};

	saradc {
		compatible = "amlogic,meson-axg-saradc";
		status = "okay";
		#io-channel-cells = <0x01>;
		clocks = <0x0a 0x0d 0x7a>;
		clock-names = "xtal\0saradc_clk";
		interrupts = <0x00 0x49 0x01>;
		reg = <0x00 0xff809000 0x00 0x38>;
		phandle = <0x5c>;
	};

	efuse {
		compatible = "amlogic, efuse";
		read_cmd = <0x82000030>;
		write_cmd = <0x82000031>;
		get_max_cmd = <0x82000033>;
		key = <0x27>;
		clocks = <0x0d 0x3d>;
		clock-names = "efuse_clk";
		status = "ok";
		phandle = <0x99>;
	};

	efusekey {
		keynum = <0x04>;
		key0 = <0x28>;
		key1 = <0x29>;
		key2 = <0x2a>;
		key3 = <0x2b>;
		phandle = <0x27>;

		key_0 {
			keyname = "mac";
			offset = <0x00>;
			size = <0x06>;
			phandle = <0x28>;
		};

		key_1 {
			keyname = "mac_bt";
			offset = <0x06>;
			size = <0x06>;
			phandle = <0x29>;
		};

		key_2 {
			keyname = "mac_wifi";
			offset = <0x0c>;
			size = <0x06>;
			phandle = <0x2a>;
		};

		key_3 {
			keyname = "usid";
			offset = <0x12>;
			size = <0x10>;
			phandle = <0x2b>;
		};
	};

	audio_data {
		compatible = "amlogic, audio_data";
		query_licence_cmd = <0x82000050>;
		status = "okay";
		phandle = <0x9a>;
	};

	ddr_bandwidth {
		compatible = "amlogic, ddr-bandwidth";
		status = "okay";
		reg = <0x00 0xff638000 0x00 0x100 0x00 0xff637000 0x00 0x100>;
		interrupts = <0x00 0x34 0x01>;
		interrupt-names = "ddr_bandwidth";
	};

	dmc_monitor {
		compatible = "amlogic, dmc_monitor";
		status = "okay";
		reg_base = <0xff638800>;
		interrupts = <0x00 0x33 0x01>;
	};

	cpu_ver_name {
		compatible = "amlogic, cpu-major-id-axg";
	};

	defendkey {
		compatible = "amlogic, defendkey";
		mem_size = <0x00 0x100000>;
		status = "okay";
		phandle = <0x9b>;
	};

	lcd {
		compatible = "amlogic, lcd-axg";
		mode = "tablet";
		status = "okay";
		key_valid = <0x00>;
		clocks = <0x0d 0x22 0x0d 0x2a 0x0d 0x72 0x0d 0x1e 0x0d 0x1f>;
		clock-names = "dsi_host_gate\0dsi_phy_gate\0dsi_meas\0mipi_enable_gate\0mipi_bandgap_gate";
		reg = <0x00 0xffd06000 0x00 0x400 0x00 0xff640000 0x00 0x100>;
		interrupts = <0x00 0x03 0x01>;
		interrupt-names = "vsync";
		pinctrl_version = <0x01>;
		lcd_cpu-gpios = <0x2c 0x06 0x00>;
		lcd_cpu_gpio_names = "GPIOZ_6";

		lcd_0 {
			model_name = "B080XAN01";
			interface = "mipi";
			basic_setting = <0x300 0x400 0x3b4 0x474 0x08 0x77 0x9f>;
			lcd_timing = <0x40 0x38 0x00 0x32 0x1e 0x00>;
			clk_attr = <0x00 0x00 0x01 0x3dd6dc0>;
			mipi_attr = <0x04 0x226 0x00 0x01 0x00 0x02 0x01 0x00>;
			dsi_init_on = <0x05 0x01 0x11 0xfd 0x01 0x14 0x05 0x01 0x29 0xfd 0x01 0x14 0xff 0x00>;
			dsi_init_off = <0x05 0x01 0x28 0xfd 0x01 0x0a 0x05 0x01 0x10 0xfd 0x01 0x0a 0xff 0x00>;
			extern_init = <0xff>;
			power_on_step = <0x00 0x00 0x00 0x0a 0x00 0x00 0x01 0x14 0x02 0x00 0x00 0x00 0xff 0x00 0x00 0x00>;
			power_off_step = <0x02 0x00 0x00 0x32 0x00 0x00 0x00 0x64 0xff 0x00 0x00 0x00>;
			backlight_index = <0x00>;
		};

		lcd_1 {
			model_name = "TV070WSM";
			interface = "mipi";
			basic_setting = <0x258 0x400 0x2a8 0x410 0x08 0x5f 0xa3>;
			lcd_timing = <0x18 0x24 0x00 0x02 0x08 0x00>;
			clk_attr = <0x00 0x00 0x01 0x286f900>;
			mipi_attr = <0x04 0x15e 0x00 0x01 0x00 0x02 0x00 0x00>;
			dsi_init_on = <0xf0 0x03 0x00 0x01 0x1e 0xf0 0x03 0x00 0x00 0x0a 0xf0 0x03 0x00 0x01 0x1e 0xff 0x00>;
			dsi_init_off = <0xff 0x00>;
			extern_init = <0x01>;
			power_on_step = <0x00 0x00 0x00 0x14 0x02 0x00 0x00 0x00 0xff 0x00 0x00 0x00>;
			power_off_step = <0x02 0x00 0x00 0x64 0x00 0x00 0x00 0x64 0xff 0x00 0x00 0x00>;
			backlight_index = <0x00>;
		};

		lcd_2 {
			model_name = "P070ACB";
			interface = "mipi";
			basic_setting = <0x258 0x400 0x2a8 0x4aa 0x08 0x03 0x05>;
			lcd_timing = <0x18 0x24 0x00 0x0a 0x50 0x00>;
			clk_attr = <0x00 0x00 0x01 0x2e755c0>;
			mipi_attr = <0x04 0x190 0x00 0x01 0x00 0x02 0x00 0x00>;
			dsi_init_on = <0xff 0x00>;
			dsi_init_off = <0xff 0x00>;
			extern_init = <0x03>;
			power_on_step = <0x00 0x00 0x01 0x14 0x00 0x00 0x00 0x0a 0x00 0x00 0x01 0x14 0x02 0x00 0x00 0x00 0xff 0x00 0x00 0x00>;
			power_off_step = <0x02 0x00 0x00 0x32 0x00 0x00 0x00 0x64 0xff 0x00 0x00 0x00>;
			backlight_index = <0x00>;
		};

		lcd_3 {
			model_name = "ST7701";
			interface = "mipi";
			basic_setting = <0x1e0 0x356 0x23a 0x3a1 0x08 0x08 0x0f>;
			lcd_timing = <0x1e 0x1e 0x00 0x05 0x28 0x00>;
			clk_attr = <0x00 0x00 0x01 0x1e4cc98>;
			mipi_attr = <0x02 0x190 0x00 0x01 0x00 0x02 0x01 0x00>;
			dsi_init_on = <0xff 0x00>;
			dsi_init_off = <0xff 0x00>;
			extern_init = <0x02>;
			power_on_step = <0x00 0x00 0x01 0x14 0x00 0x00 0x00 0x0a 0x00 0x00 0x01 0x14 0x02 0x00 0x00 0x00 0xff 0x00 0x00 0x00>;
			power_off_step = <0x02 0x00 0x00 0x32 0x00 0x00 0x00 0x64 0xff 0x00 0x00 0x00>;
			backlight_index = <0x00>;
		};

		lcd_4 {
			model_name = "480p";
			interface = "mipi";
			basic_setting = <0x2d0 0x1e0 0x35a 0x20d 0x08 0x0f 0x08>;
			lcd_timing = <0x3e 0x3c 0x00 0x06 0x1e 0x00>;
			clk_attr = <0x00 0x00 0x01 0x19c6638>;
			mipi_attr = <0x02 0x14a 0x00 0x00 0x00 0x01 0x00 0x01>;
			dsi_init_on = <0xff 0x00>;
			dsi_init_off = <0xff 0x00>;
			extern_init = <0xff>;
			power_on_step = <0x00 0x00 0x00 0x14 0x02 0x00 0x00 0x00 0xff 0x00 0x00 0x00>;
			power_off_step = <0x02 0x00 0x00 0x64 0x00 0x00 0x00 0x64 0xff 0x00 0x00 0x00>;
			backlight_index = <0x00>;
		};

		lcd_5 {
			model_name = "720p";
			interface = "mipi";
			basic_setting = <0x500 0x2d0 0x672 0x2ee 0x08 0x10 0x09>;
			lcd_timing = <0x28 0xdc 0x00 0x05 0x14 0x00>;
			clk_attr = <0x00 0x00 0x01 0x46cf710>;
			mipi_attr = <0x04 0x1f4 0x00 0x00 0x00 0x00 0x01 0x00>;
			dsi_init_on = <0xff 0x00>;
			dsi_init_off = <0xff 0x00>;
			extern_init = <0xff>;
			power_on_step = <0x00 0x00 0x00 0x0a 0x00 0x00 0x01 0x14 0x02 0x00 0x00 0x00 0xff 0x00 0x00 0x00>;
			power_off_step = <0x02 0x00 0x00 0x32 0x00 0x00 0x00 0x64 0xff 0x00 0x00 0x00>;
			backlight_index = <0x00>;
		};
	};

	lcd_extern {
		compatible = "amlogic, lcd_extern";
		status = "okay";
		i2c_bus = "i2c_bus_1";
		key_valid = <0x00>;

		extern_0 {
			index = <0x00>;
			extern_name = "mipi_default";
			status = "okay";
			type = <0x02>;
			cmd_size = <0xff>;
			init_on = <0xfd 0x01 0x0a 0x05 0x01 0x11 0xfd 0x01 0x78 0x05 0x01 0x29 0xff 0x00>;
			init_off = <0x05 0x01 0x28 0xfd 0x01 0x0a 0x05 0x01 0x10 0xfd 0x01 0x96 0xff 0x00>;
		};

		extern_1 {
			index = <0x01>;
			extern_name = "mipi_default";
			status = "okay";
			type = <0x02>;
			cmd_size = <0xff>;
			init_on = <0xfd 0x01 0x0a 0x15 0x02 0x62 0x01 0x39 0x05 0xff 0xaa 0x55 0x25 0x01 0x15 0x02 0xfc 0x08 0xfd 0x01 0x01 0x15 0x02 0xfc 0x00 0x39 0x05 0xff 0xaa 0x55 0x25 0x00 0xfd 0x01 0x14 0x39 0x06 0xf0 0x55 0xaa 0x52 0x08 0x00 0x39 0x03 0xb1 0x68 0x41 0x15 0x02 0xb5 0x88 0x15 0x02 0xb6 0x0f 0x39 0x05 0xb8 0x01 0x01 0x12 0x01 0x39 0x03 0xbb 0x11 0x11 0x39 0x03 0xbc 0x05 0x05 0x15 0x02 0xc7 0x03 0x39 0x06 0xbd 0x03 0x02 0x19 0x17 0x00 0x15 0x02 0xc8 0x80 0x39 0x06 0xf0 0x55 0xaa 0x52 0x08 0x01 0x39 0x03 0xb2 0x01 0x01 0x39 0x03 0xb3 0x28 0x28 0x39 0x03 0xb4 0x14 0x14 0x39 0x03 0xb8 0x05 0x05 0x39 0x03 0xb9 0x45 0x45 0x39 0x03 0xba 0x25 0x25 0x39 0x03 0xbc 0x88 0x00 0x39 0x03 0xbd 0x88 0x00 0x39 0x06 0xf0 0x55 0xaa 0x52 0x08 0x02 0x15 0x02 0xee 0x00 0x39 0x11 0xb0 0x00 0x4b 0x00 0x5c 0x00 0x79 0x00 0x94 0x00 0xa6 0x00 0xd8 0x00 0xf2 0x01 0x19 0x39 0x11 0xb1 0x01 0x39 0x01 0x77 0x01 0xa2 0x01 0xf2 0x02 0x32 0x02 0x34 0x02 0x6d 0x02 0xa2 0x39 0x11 0xb2 0x02 0xc7 0x02 0xf2 0x03 0x18 0x03 0x43 0x03 0x65 0x03 0x86 0x03 0x8f 0x03 0x94 0x39 0x05 0xb3 0x03 0x96 0x03 0x98 0x39 0x11 0xb4 0x00 0x84 0x00 0x91 0x00 0xa4 0x00 0xb6 0x00 0xca 0x00 0xe9 0x01 0x02 0x01 0x2a 0x39 0x11 0xb5 0x01 0x49 0x01 0x82 0x01 0xaf 0x01 0xf7 0x02 0x36 0x02 0x38 0x02 0x70 0x02 0xa6 0x39 0x11 0xb6 0x02 0xc8 0x02 0xf5 0x03 0x1a 0x03 0x43 0x03 0x62 0x03 0x82 0x03 0x8f 0x03 0x94 0x39 0x05 0xb7 0x03 0x96 0x03 0x98 0x39 0x11 0xb8 0x01 0x22 0x01 0x27 0x01 0x2e 0x01 0x38 0x01 0x40 0x01 0x53 0x01 0x60 0x01 0x7b 0x39 0x11 0xb9 0x01 0x8c 0x01 0xb5 0x01 0xd3 0x02 0x11 0x02 0x49 0x02 0x4a 0x02 0x7f 0x02 0xb1 0x39 0x11 0xba 0x02 0xd1 0x03 0x00 0x03 0x22 0x03 0x49 0x03 0x60 0x03 0x7a 0x03 0x8b 0x03 0x8f 0x39 0x05 0xbb 0x03 0x93 0x03 0x9a 0x39 0x11 0xbc 0x00 0x37 0x00 0x48 0x00 0x65 0x00 0x80 0x00 0x92 0x00 0xc4 0x00 0xde 0x01 0x05 0x39 0x11 0xbd 0x01 0x31 0x01 0x6f 0x01 0x9e 0x01 0xee 0x02 0x32 0x02 0x34 0x02 0x71 0x02 0xa7 0x39 0x11 0xbe 0x02 0xd3 0x02 0xfe 0x03 0x24 0x03 0x4f 0x03 0x71 0x03 0x92 0x03 0x9b 0x03 0xa0 0x39 0x05 0xbf 0x03 0xa6 0x03 0xa8 0x39 0x11 0xc0 0x00 0x70 0x00 0x7d 0x00 0x90 0x00 0xa4 0x00 0xb6 0x00 0xd5 0x00 0xee 0x01 0x16 0x39 0x11 0xc1 0x01 0x41 0x01 0x7a 0x01 0xab 0x01 0xf3 0x02 0x36 0x02 0x38 0x02 0x74 0x02 0xaa 0x39 0x11 0xc2 0x02 0xd4 0x03 0x01 0x03 0x26 0x03 0x4f 0x03 0x6e 0x03 0x8e 0x03 0x9b 0x03 0xa0 0x39 0x05 0xc3 0x03 0xa6 0x03 0xa8 0x39 0x11 0xc4 0x01 0x0e 0x01 0x13 0x01 0x1a 0x01 0x24 0x01 0x2c 0x01 0x3f 0x01 0x4c 0x01 0x67 0x39 0x11 0xc5 0x01 0x84 0x01 0xad 0x01 0xcf 0x02 0x0d 0x02 0x49 0x02 0x4a 0x02 0x83 0x02 0xb5 0x39 0x11 0xc6 0x02 0xdd 0x03 0x0c 0x03 0x2e 0x03 0x55 0x03 0x6b 0x03 0x86 0x03 0x97 0x03 0x9b 0x39 0x05 0xc7 0x03 0xa1 0x03 0xa8 0x39 0x06 0xf0 0x55 0xaa 0x52 0x08 0x04 0x39 0x06 0xb1 0x03 0x02 0x02 0x02 0x00 0x39 0x06 0xf0 0x55 0xaa 0x52 0x08 0x06 0x39 0x03 0xb0 0x11 0x11 0x39 0x03 0xb1 0x13 0x13 0x39 0x03 0xb2 0x03 0x03 0x39 0x03 0xb3 0x34 0x34 0x39 0x03 0xb4 0x34 0x34 0x39 0x03 0xb5 0x34 0x34 0x39 0x03 0xb6 0x34 0x34 0x39 0x03 0xb7 0x34 0x34 0x39 0x03 0xb8 0x34 0x34 0x39 0x03 0xb9 0x34 0x34 0x39 0x03 0xba 0x34 0x34 0x39 0x03 0xbb 0x34 0x34 0x39 0x03 0xbc 0x34 0x34 0x39 0x03 0xbd 0x34 0x34 0x39 0x03 0xbe 0x34 0x34 0x39 0x03 0xbf 0x34 0x34 0x39 0x03 0xc0 0x34 0x34 0x39 0x03 0xc1 0x02 0x02 0x39 0x03 0xc2 0x12 0x12 0x39 0x03 0xc3 0x10 0x10 0x39 0x03 0xe5 0x34 0x34 0x39 0x06 0xd8 0x00 0x00 0x00 0x00 0x00 0x39 0x06 0xd9 0x00 0x00 0x00 0x00 0x00 0x39 0x06 0xf0 0x55 0xaa 0x52 0x08 0x05 0x15 0x02 0xc0 0x03 0x15 0x02 0xc1 0x02 0x39 0x03 0xc8 0x01 0x20 0x15 0x02 0xe5 0x03 0x15 0x02 0xe6 0x03 0x15 0x02 0xe7 0x03 0x15 0x02 0xe8 0x03 0x15 0x02 0xe9 0x03 0x39 0x05 0xd1 0x03 0x00 0x3d 0x00 0x39 0x06 0xf0 0x55 0xaa 0x52 0x08 0x03 0x39 0x03 0xb0 0x11 0x00 0x39 0x03 0xb1 0x11 0x00 0x39 0x06 0xb2 0x03 0x00 0x00 0x00 0x00 0x39 0x06 0xb3 0x03 0x00 0x00 0x00 0x00 0x39 0x06 0xba 0x31 0x00 0x00 0x00 0x00 0x15 0x02 0x35 0x00 0x15 0x02 0x51 0xff 0x15 0x02 0x53 0x2c 0x15 0x02 0x55 0x03 0x05 0x01 0x11 0xfd 0x01 0x78 0x05 0x01 0x29 0xfd 0x01 0x82 0xff 0x00>;
			init_off = <0x05 0x01 0x28 0xfd 0x01 0x0a 0x05 0x01 0x10 0xfd 0x01 0x96 0xff 0x00>;
		};

		extern_2 {
			index = <0x02>;
			extern_name = "mipi_default";
			status = "okay";
			type = <0x02>;
			init_on = <0x13 0x01 0x11 0xfd 0x01 0xc8 0x29 0x06 0xff 0x77 0x01 0x00 0x00 0x10 0x29 0x03 0xc0 0xe9 0x03 0x29 0x03 0xc1 0x11 0x02 0x29 0x03 0xc2 0x31 0x08 0x29 0x11 0xb0 0x00 0x06 0x11 0x12 0x18 0x0a 0x0a 0x09 0x09 0x1d 0x09 0x14 0x10 0x0e 0x11 0x19 0x29 0x11 0xb1 0x00 0x06 0x11 0x11 0x15 0x09 0x0b 0x09 0x09 0x23 0x09 0x17 0x14 0x18 0x1e 0x19 0x29 0x06 0xff 0x77 0x01 0x00 0x00 0x11 0x23 0x02 0xb0 0x4d 0x23 0x02 0xb1 0x3a 0x23 0x02 0xb2 0x07 0x23 0x02 0xb3 0x80 0x23 0x02 0xb5 0x47 0x23 0x02 0xb7 0x8a 0x23 0x02 0xb8 0x21 0x23 0x02 0xc1 0x78 0x23 0x02 0xc2 0x78 0x23 0x02 0xd0 0x88 0xfd 0x01 0x64 0x29 0x04 0xe0 0x00 0x00 0x02 0x29 0x0c 0xe1 0x08 0x00 0x0a 0x00 0x07 0x00 0x09 0x00 0x00 0x33 0x33 0x29 0x0e 0xe2 0x00 0x00 0x00 0x00 0x00 0x00 0x00 0x00 0x00 0x00 0x00 0x00 0x00 0x29 0x05 0xe3 0x00 0x00 0x33 0x33 0x29 0x03 0xe4 0x44 0x44 0x29 0x11 0xe5 0x0e 0x60 0xaf 0xaf 0x10 0x60 0xaf 0xaf 0x0a 0x60 0xaf 0xaf 0x0c 0x60 0xaf 0xaf 0x29 0x05 0xe6 0x00 0x00 0x33 0x33 0x29 0x03 0xe7 0x44 0x44 0x29 0x11 0xe8 0x0d 0x60 0xa0 0xa0 0x0f 0x60 0xaf 0xaf 0x09 0x60 0xaf 0xaf 0x0b 0x60 0xaf 0xaf 0x29 0x08 0xeb 0x02 0x01 0xe4 0xe4 0x44 0x00 0x40 0x29 0x03 0xec 0x02 0x01 0x29 0x11 0xed 0xab 0x89 0x76 0x54 0x01 0xff 0xff 0xff 0xff 0xff 0xff 0x10 0x45 0x67 0x98 0xba 0xfd 0x01 0x0a 0x29 0x06 0xff 0x77 0x01 0x00 0x00 0x00 0x13 0x01 0x29 0xfd 0x01 0xc8 0xff 0x00>;
			init_off = <0x05 0x01 0x28 0xfd 0x01 0x0a 0x05 0x01 0x10 0xfd 0x01 0x96 0xff 0x00>;
		};

		extern_3 {
			index = <0x03>;
			extern_name = "mipi_default";
			status = "okay";
			type = <0x02>;
			cmd_size = <0xff>;
			init_on = <0x29 0x05 0xff 0xaa 0x55 0x25 0x01 0x23 0x02 0xfc 0x08 0xfd 0x01 0x01 0x23 0x02 0xfc 0x00 0xfd 0x01 0x01 0x23 0x02 0x6f 0x21 0x23 0x02 0xf7 0x01 0xfd 0x01 0x01 0x23 0x02 0x6f 0x21 0x23 0x02 0xf7 0x00 0xfd 0x01 0x01 0x23 0x02 0x6f 0x1a 0x23 0x02 0xf7 0x05 0xfd 0x01 0x01 0x29 0x05 0xff 0xaa 0x55 0x25 0x00 0x29 0x06 0xf0 0x55 0xaa 0x52 0x08 0x00 0x29 0x03 0xb1 0x68 0x41 0x23 0x02 0xb5 0x88 0x29 0x06 0xbd 0x02 0xb0 0x0c 0x14 0x00 0x23 0x02 0xc8 0x80 0x29 0x06 0xf0 0x55 0xaa 0x52 0x08 0x01 0x29 0x03 0xb3 0x2d 0x2d 0x29 0x03 0xb4 0x19 0x19 0x23 0x02 0xb5 0x06 0x29 0x03 0xb9 0x36 0x36 0x29 0x03 0xba 0x26 0x26 0x29 0x03 0xbc 0xa8 0x01 0x29 0x03 0xbd 0xab 0x01 0x23 0x02 0xc0 0x0c 0x29 0x06 0xf0 0x55 0xaa 0x52 0x08 0x02 0x23 0x02 0xee 0x02 0x29 0x07 0xb0 0x00 0x50 0x00 0x52 0x00 0x73 0x23 0x02 0x6f 0x06 0x29 0x07 0xb0 0x00 0x8f 0x00 0xa5 0x00 0xca 0x23 0x02 0x6f 0x0c 0x29 0x05 0xb0 0x00 0xea 0x01 0x1b 0x29 0x07 0xb1 0x01 0x42 0x01 0x82 0x01 0xb3 0x23 0x02 0x6f 0x06 0x29 0x07 0xb1 0x02 0x00 0x02 0x41 0x02 0x42 0x23 0x02 0x6f 0x0c 0x29 0x05 0xb1 0x02 0x78 0x02 0xb5 0x29 0x07 0xb2 0x02 0xda 0x03 0x12 0x03 0x3a 0x23 0x02 0x6f 0x06 0x29 0x07 0xb2 0x03 0x6e 0x03 0x8d 0x03 0xb1 0x23 0x02 0x6f 0x0c 0x29 0x05 0xb2 0x03 0xca 0x03 0xe8 0x29 0x05 0xb3 0x03 0xf4 0x03 0xff 0x29 0x07 0xbc 0x00 0x05 0x00 0x52 0x00 0x73 0x23 0x02 0x6f 0x06 0x29 0x07 0xbc 0x00 0x8f 0x00 0xa5 0x00 0xca 0x23 0x02 0x6f 0x0c 0x29 0x05 0xbc 0x00 0xea 0x01 0x1b 0x29 0x07 0xbd 0x01 0x42 0x01 0x82 0x01 0xb3 0x23 0x02 0x6f 0x06 0x29 0x07 0xbd 0x02 0x00 0x02 0x41 0x02 0x42 0x23 0x02 0x6f 0x0c 0x29 0x05 0xbd 0x02 0x78 0x02 0xb5 0x29 0x07 0xbe 0x02 0xda 0x03 0x12 0x03 0x3a 0x23 0x02 0x6f 0x06 0x29 0x07 0xbe 0x03 0x6e 0x03 0x8d 0x03 0xb1 0x23 0x02 0x6f 0x0c 0x29 0x05 0xbe 0x03 0xca 0x03 0xe8 0x29 0x05 0xbf 0x03 0xf4 0x03 0xff 0x29 0x06 0xf0 0x55 0xaa 0x52 0x08 0x03 0x29 0x06 0xb2 0x05 0x00 0x00 0x00 0x00 0x29 0x06 0xb6 0x05 0x00 0x00 0x00 0x00 0x29 0x06 0xb7 0x05 0x00 0x00 0x00 0x00 0x29 0x06 0xba 0x57 0x00 0x00 0x00 0x00 0x29 0x06 0xbb 0x57 0x00 0x00 0x00 0x00 0x29 0x05 0xc0 0x00 0x34 0x00 0x00 0x29 0x05 0xc1 0x00 0x00 0x34 0x00 0x23 0x02 0xc4 0x40 0x29 0x06 0xf0 0x55 0xaa 0x52 0x08 0x05 0x29 0x03 0xb0 0x17 0x06 0x29 0x03 0xb1 0x17 0x06 0x29 0x03 0xb2 0x17 0x06 0x29 0x03 0xb3 0x17 0x06 0x29 0x03 0xb4 0x17 0x06 0x29 0x06 0xbd 0x03 0x01 0x03 0x03 0x01 0x23 0x02 0xc0 0x05 0x23 0x02 0xc4 0x82 0x23 0x02 0xc5 0xa2 0x29 0x03 0xc8 0x03 0x30 0x29 0x03 0xc9 0x03 0x31 0x29 0x04 0xcc 0x00 0x00 0x3c 0x29 0x04 0xcd 0x00 0x00 0x3c 0x29 0x06 0xd1 0x00 0x44 0x09 0x00 0x00 0x29 0x06 0xd2 0x00 0x04 0x0b 0x00 0x00 0x29 0x06 0xf0 0x55 0xaa 0x52 0x08 0x06 0x29 0x03 0xb0 0x0b 0x2d 0x29 0x03 0xb1 0x2d 0x09 0x29 0x03 0xb2 0x2a 0x29 0x29 0x03 0xb3 0x34 0x1b 0x29 0x03 0xb4 0x19 0x17 0x29 0x03 0xb5 0x15 0x13 0x29 0x03 0xb6 0x11 0x01 0x29 0x03 0xb7 0x34 0x34 0x29 0x03 0xb8 0x34 0x2d 0x29 0x03 0xb9 0x2d 0x34 0x29 0x03 0xba 0x2d 0x2d 0x29 0x03 0xbb 0x34 0x34 0x29 0x03 0xbc 0x34 0x34 0x29 0x03 0xbd 0x00 0x10 0x29 0x03 0xbe 0x12 0x14 0x29 0x03 0xbf 0x16 0x18 0x29 0x03 0xc0 0x1a 0x34 0x29 0x03 0xc1 0x29 0x2a 0x29 0x03 0xc2 0x08 0x2d 0x29 0x03 0xc3 0x2d 0x0a 0x29 0x03 0xc4 0x0a 0x2d 0x29 0x03 0xc5 0x2d 0x00 0x29 0x03 0xc6 0x2a 0x29 0x29 0x03 0xc7 0x34 0x14 0x29 0x03 0xc8 0x16 0x18 0x29 0x03 0xc9 0x1a 0x10 0x29 0x03 0xca 0x12 0x08 0x29 0x03 0xcb 0x34 0x34 0x29 0x03 0xcc 0x34 0x2d 0x29 0x03 0xcd 0x2d 0x34 0x29 0x03 0xce 0x2d 0x2d 0x29 0x03 0xcf 0x34 0x34 0x29 0x03 0xd0 0x34 0x34 0x29 0x03 0xd1 0x09 0x13 0x29 0x03 0xd2 0x11 0x1b 0x29 0x03 0xd3 0x19 0x17 0x29 0x03 0xd4 0x15 0x34 0x29 0x03 0xd5 0x29 0x2a 0x29 0x03 0xd6 0x01 0x2d 0x29 0x03 0xd7 0x2d 0x0b 0x29 0x06 0xd8 0x00 0x00 0x00 0x00 0x00 0x29 0x06 0xd9 0x00 0x00 0x00 0x00 0x00 0x29 0x03 0xe5 0x34 0x34 0x29 0x03 0xe6 0x34 0x34 0x23 0x02 0xe7 0x00 0x29 0x03 0xe8 0x34 0x34 0x29 0x03 0xe9 0x34 0x34 0x23 0x02 0xea 0x00 0x29 0x06 0xf0 0x55 0xaa 0x52 0x00 0x00 0x13 0x01 0x35 0x13 0x01 0x11 0xfd 0x01 0x78 0x13 0x01 0x29 0xfd 0x01 0x14 0xff 0x00>;
			init_off = <0x05 0x01 0x28 0xfd 0x01 0x0a 0x05 0x01 0x10 0xfd 0x01 0x96 0xff 0x00>;
		};
	};

	backlight {
		compatible = "amlogic, backlight-axg";
		status = "okay";
		key_valid = <0x00>;
		pinctrl-names = "pwm_on\0pwm_off";
		pinctrl-0 = <0x2d>;
		pinctrl-1 = <0x2e>;
		pinctrl_version = <0x01>;
		bl_pwm_config = <0x2f>;
		bl-gpios = <0x2c 0x04 0x00 0x2c 0x05 0x00>;
		bl_gpio_names = "GPIOZ_4\0GPIOZ_5";

		backlight_0 {
			index = <0x00>;
			bl_name = "backlight_pwm";
			bl_level_default_uboot_kernel = <0x64 0x64>;
			bl_level_attr = <0xff 0x0a 0x80 0x80>;
			bl_ctrl_method = <0x01>;
			bl_power_attr = <0x01 0x01 0x00 0xc8 0xc8>;
			bl_pwm_port = "PWM_B";
			bl_pwm_attr = <0x00 0xb4 0x64 0x19>;
			bl_pwm_power = <0x00 0x01 0x0a 0x0a>;
			bl_pwm_en_sequence_reverse = <0x00>;
		};

		backlight_1 {
			index = <0x01>;
			bl_name = "bl_extern";
			bl_level_default_uboot_kernel = <0x64 0x64>;
			bl_level_attr = <0xff 0x0a 0x80 0x80>;
			bl_ctrl_method = <0x04>;
			bl_power_attr = <0x01 0x01 0x00 0xc8 0xc8>;
			bl_extern_index = <0x01>;
		};
	};

	bl_pwm_conf {
		phandle = <0x2f>;

		pwm_channel_0 {
			pwm_port_index = <0x01>;
			pwms = <0x30 0x01 0x7558 0x00>;
		};
	};

	bl_extern {
		compatible = "amlogic, bl_extern";
		status = "disabled";
		i2c_bus = "i2c_bus_3";

		extern_0 {
			index = <0x00>;
			extern_name = "i2c_lp8556";
			type = <0x00>;
			i2c_address = <0x2c>;
			dim_max_min = <0xff 0x0a>;
		};

		extern_1 {
			index = <0x01>;
			extern_name = "mipi_lt070me05";
			type = <0x02>;
			dim_max_min = <0xff 0x0a>;
		};
	};

	aliases {
		serial0 = "/soc/aobus@ff800000/serial@3000";
		serial1 = "/serial@ffd24000";
	};

	memory@00000000 {
		device_type = "memory";
		linux,usable-memory = <0x00 0x00 0x00 0x40000000>;
	};

	reserved-memory {
		#address-cells = <0x02>;
		#size-cells = <0x02>;
		ranges;

		ramoops@0x07400000 {
			compatible = "ramoops";
			reg = <0x00 0x7400000 0x00 0x100000>;
			record-size = <0x8000>;
			console-size = <0x8000>;
			ftrace-size = <0x40000>;
		};

		linux,secmon {
			compatible = "shared-dma-pool";
			reusable;
			size = <0x00 0x400000>;
			alignment = <0x00 0x400000>;
			alloc-ranges = <0x00 0x5000000 0x00 0x400000>;
			phandle = <0x08>;
		};

		linux,secos {
			status = "disable";
			compatible = "amlogic, aml_secos_memory";
			reg = <0x00 0x5300000 0x00 0x2000000>;
			no-map;
			phandle = <0x9c>;
		};

		linux,meson-fb {
			compatible = "shared-dma-pool";
			reusable;
			size = <0x00 0x2000000>;
			alignment = <0x00 0x400000>;
			alloc-ranges = <0x00 0x3e000000 0x00 0x2000000>;
			phandle = <0x5b>;
		};
	};

	mtd_nand {
		compatible = "amlogic, aml_mtd_nand";
		dev_name = "mtdnand";
		status = "okay";
		reg = <0x00 0xffe07800 0x00 0x200>;
		interrupts = <0x00 0x22 0x01>;
		pinctrl-names = "nand_rb_mod\0nand_norb_mod\0nand_cs_only";
		pinctrl-0 = <0x31>;
		pinctrl-1 = <0x31>;
		pinctrl-2 = <0x32>;
		device_id = <0x00>;
		clocks = <0x0d 0x53>;
		clock-names = "core";
		bl_mode = <0x01>;
		fip_copies = <0x04>;
		fip_size = <0x200000>;
		nand_clk_ctrl = <0xffe07000>;
		plat-names = "bootloader\0nandnormal";
		plat-num = <0x02>;
		plat-part-0 = <0x33>;
		plat-part-1 = <0x34>;

		bootloader {
			enable_pad = "ce0";
			busy_pad = "rb0";
			timming_mode = "mode5";
			bch_mode = "bch8_1k";
			t_rea = <0x14>;
			t_rhoh = <0x0f>;
			chip_num = <0x01>;
			part_num = <0x00>;
			rb_detect = <0x01>;
			phandle = <0x33>;
		};

		nandnormal {
			enable_pad = "ce0";
			busy_pad = "rb0";
			timming_mode = "mode5";
			bch_mode = "bch8_1k";
			plane_mode = "twoplane";
			t_rea = <0x14>;
			t_rhoh = <0x0f>;
			chip_num = <0x02>;
			part_num = <0x03>;
			partition = <0x35>;
			rb_detect = <0x01>;
			phandle = <0x34>;
		};

		nand_partition {
			phandle = <0x35>;

			tpl {
				offset = <0x00 0x00>;
				size = <0x00 0x00>;
			};

			misc {
				offset = <0x00 0x00>;
				size = <0x00 0x200000>;
			};

			logo {
				offset = <0x00 0x00>;
				size = <0x00 0x200000>;
			};

			recovery {
				offset = <0x00 0x00>;
				size = <0x00 0x1000000>;
			};

			boot {
				offset = <0x00 0x00>;
				size = <0x00 0xf00000>;
			};

			system {
				offset = <0x00 0x00>;
				size = <0x00 0x11800000>;
			};

			data {
				offset = <0xffffffff 0xffffffff>;
				size = <0x00 0x00>;
			};
		};
	};

	ethernet@0xff3f0000 {
		compatible = "amlogic, gxbb-eth-dwmac";
		reg = <0x00 0xff3f0000 0x00 0x10000 0x00 0xff634540 0x00 0x08 0x00 0xff634558 0x00 0x0c 0x00 0xffd01008 0x00 0x04>;
		interrupts = <0x00 0x08 0x01>;
		pinctrl-names = "external_eth_pins";
		pinctrl-0 = <0x36>;
		mc_val_internal_phy = <0x1800>;
		mc_val_external_phy = <0x1621>;
		interrupt-names = "macirq";
		clocks = <0x0d 0x35>;
		clock-names = "ethclk81";
		internal_phy = <0x00>;
		phandle = <0x9d>;
	};

	aml-sensor@0 {
		compatible = "amlogic, aml-thermal";
		device_name = "thermal";
		#thermal-sensor-cells = <0x01>;
		phandle = <0x37>;

		cooling_devices {

			cpufreq_cool_cluster0 {
				min_state = <0xf4240>;
				dyn_coeff = <0x8c>;
				cluster_id = <0x00>;
				node_name = "cpufreq_cool0";
				device_type = "cpufreq";
			};

			cpucore_cool_cluster0 {
				min_state = <0x01>;
				dyn_coeff = <0x00>;
				cluster_id = <0x00>;
				node_name = "cpucore_cool0";
				device_type = "cpucore";
			};
		};

		cpufreq_cool0 {
			#cooling-cells = <0x02>;
			phandle = <0x39>;
		};

		cpucore_cool0 {
			#cooling-cells = <0x02>;
			phandle = <0x3a>;
		};
	};

	thermal-zones {

		soc_thermal {
			polling-delay = <0x3e8>;
			polling-delay-passive = <0x64>;
			sustainable-power = <0x41a>;
			thermal-sensors = <0x37 0x03>;

			trips {

				trip-point@0 {
					temperature = <0x11170>;
					hysteresis = <0x3e8>;
					type = "passive";
					phandle = <0x9e>;
				};

				trip-point@1 {
					temperature = <0x13880>;
					hysteresis = <0x3e8>;
					type = "passive";
					phandle = <0x38>;
				};

				trip-point@2 {
					temperature = <0x14c08>;
					hysteresis = <0x1388>;
					type = "hot";
					phandle = <0x9f>;
				};

				trip-point@3 {
					temperature = <0x3f7a0>;
					hysteresis = <0x3e8>;
					type = "critical";
					phandle = <0xa0>;
				};
			};

			cooling-maps {

				cpufreq_cooling_map {
					trip = <0x38>;
					cooling-device = <0x39 0x00 0x04>;
					contribution = <0x400>;
				};

				cpucore_cooling_map {
					trip = <0x38>;
					cooling-device = <0x3a 0x00 0x03>;
					contribution = <0x400>;
				};
			};
		};
	};

	dwc3@ff500000 {
		compatible = "synopsys, dwc3";
		status = "okay";
		reg = <0x00 0xff500000 0x00 0x100000>;
		interrupts = <0x00 0x1e 0x04>;
		usb-phy = <0x3b 0x3c>;
		cpu-type = "gxl";
		clock-src = "usb3.0";
		clocks = <0x0d 0x3b>;
		clock-names = "dwc_general";
		phandle = <0xa1>;
	};

	usb2phy@ffe09000 {
		compatible = "amlogic, amlogic-new-usb2";
		status = "okay";
		portnum = <0x04>;
		reg = <0x00 0xffe09000 0x00 0x80 0x00 0xffd01008 0x00 0x04>;
		phandle = <0x3b>;
	};

	usb3phy@ffe09080 {
		compatible = "amlogic, amlogic-new-usb3";
		status = "okay";
		portnum = <0x00>;
		reg = <0x00 0xffe09080 0x00 0x20>;
		interrupts = <0x00 0x10 0x04>;
		otg = <0x01>;
		gpio-vbus-power = "GPIOAO_5";
		gpios = <0x0f 0x05 0x00>;
		phandle = <0x3c>;
	};

	dwc2_a {
		compatible = "amlogic, dwc2";
		device_name = "dwc2_a";
		reg = <0x00 0xff400000 0x00 0x40000>;
		status = "okay";
		interrupts = <0x00 0x1f 0x04>;
		pl-periph-id = <0x00>;
		clock-src = "usb0";
		port-id = <0x00>;
		port-type = <0x02>;
		port-speed = <0x00>;
		port-config = <0x00>;
		port-dma = <0x00>;
		port-id-mode = <0x00>;
		usb-fifo = <0x2d8>;
		cpu-type = "gxl";
		controller-type = <0x03>;
		phy-reg = <0xffe09000>;
		phy-reg-size = <0xa0>;
		clocks = <0x0d 0x3b 0x0d 0x41 0x0d 0x39>;
		clock-names = "usb_general\0usb1\0usb1_to_ddr";
	};

	pcieA@f9800000 {
		compatible = "amlogic, amlogic-pcie\0snps,dw-pcie";
		reg = <0x00 0xf9800000 0x00 0x400000 0x00 0xff646000 0x00 0x2000 0x00 0xf9f00000 0x00 0x100000 0x00 0xff644000 0x00 0x2000 0x00 0xffd01080 0x00 0x10>;
		reg-names = "elbi\0cfg\0config\0phy\0reset";
		reset-gpio = <0x2c 0x42 0x00>;
		interrupts = <0x00 0xb1 0x00>;
		#interrupt-cells = <0x01>;
		interrupt-map-mask = <0x00 0x00 0x00 0x00>;
		interrupt-map = <0x00 0x00 0x00 0x00 0x01 0x00 0xb3 0x01>;
		bus-range = <0x00 0xff>;
		#address-cells = <0x03>;
		#size-cells = <0x02>;
		device_type = "pci";
		ranges = <0x82000000 0x00 0x00 0x00 0xf9c00000 0x00 0x300000>;
		num-lanes = <0x01>;
		pcie-num = <0x01>;
		clocks = <0x0d 0x3b 0x0d 0x18 0x0d 0x1e 0x0d 0x1f 0x0d 0x2c 0x0d 0x1c>;
		clock-names = "pcie_general\0pcie_refpll\0pcie_mipi_enable_gate\0pcie_mipi_bandgap_gate\0pcie\0port";
		gpio-type = <0x02>;
		status = "okay";
		phandle = <0xa2>;
	};

	pcieB@fa000000 {
		compatible = "amlogic, amlogic-pcie\0snps,dw-pcie";
		reg = <0x00 0xfa000000 0x00 0x400000 0x00 0xff648000 0x00 0x2000 0x00 0xfa400000 0x00 0x100000 0x00 0xff644000 0x00 0x2000 0x00 0xffd01080 0x00 0x10>;
		reg-names = "elbi\0cfg\0config\0phy\0reset";
		reset-gpio = <0x2c 0x0a 0x00>;
		interrupts = <0x00 0xa7 0x00>;
		#interrupt-cells = <0x01>;
		bus-range = <0x00 0xff>;
		#address-cells = <0x03>;
		#size-cells = <0x02>;
		interrupt-map-mask = <0x00 0x00 0x00 0x00>;
		interrupt-map = <0x00 0x00 0x00 0x00 0x01 0x00 0xa9 0x01>;
		device_type = "pci";
		ranges = <0x81000000 0x00 0x00 0x00 0xfa500000 0x00 0x10000 0x82000000 0x00 0xfa510000 0x00 0xfa510000 0x00 0x2f0000>;
		num-lanes = <0x01>;
		pcie-num = <0x02>;
		clocks = <0x0d 0x3b 0x0d 0x18 0x0d 0x1e 0x0d 0x1f 0x0d 0x2d 0x0d 0x1d>;
		clock-names = "pcie_general\0pcie_refpll\0pcie_mipi_enable_gate\0pcie_mipi_bandgap_gate\0pcie\0port";
		gpio-type = <0x01>;
		status = "okay";
		phandle = <0xa3>;
	};

	serial@ffd24000 {
		compatible = "amlogic, meson-uart";
		reg = <0x00 0xffd24000 0x00 0x18>;
		interrupts = <0x00 0x1a 0x01>;
		status = "okay";
		clocks = <0x0a 0x0d 0x29>;
		clock-names = "clk_uart\0clk_gate";
		fifosize = <0x80>;
		pinctrl-names = "default";
		pinctrl-0 = <0x3d>;
		phandle = <0xa4>;
	};

	serial@ffd23000 {
		compatible = "amlogic, meson-uart";
		reg = <0x00 0xffd23000 0x00 0x18>;
		interrupts = <0x00 0x4b 0x01>;
		status = "disable";
		clocks = <0x0a 0x0d 0x36>;
		clock-names = "clk_uart\0clk_gate";
		fifosize = <0x40>;
		pinctrl-names = "default";
		pinctrl-0 = <0x3e>;
		phandle = <0xa5>;
	};

	vpu {
		compatible = "amlogic, vpu-axg";
		dev_name = "vpu";
		status = "okay";
		clocks = <0x0d 0x6d 0x0d 0x44 0x0d 0x5f 0x0d 0x63 0x0d 0x64>;
		clock-names = "vapb_clk\0vpu_intr_gate\0vpu_clk0\0vpu_clk1\0vpu_clk";
		clk_level = <0x03>;
	};

	vout {
		compatible = "amlogic, vout";
		dev_name = "vout";
		status = "okay";
	};

	aml_snd_iomap {
		compatible = "amlogic, snd-iomap";
		status = "okay";
		#address-cells = <0x02>;
		#size-cells = <0x02>;
		ranges;

		pdm_bus {
			reg = <0x00 0xff632000 0x00 0x2000>;
		};

		audiobus_base {
			reg = <0x00 0xff642000 0x00 0x2000>;
		};

		audiolocker_base {
			reg = <0x00 0xff64a000 0x00 0x2000>;
		};
	};

	dummy {
		#sound-dai-cells = <0x00>;
		compatible = "amlogic, aml_dummy_codec";
		status = "okay";
		phandle = <0x40>;
	};

	auge_sound {
		compatible = "amlogic, axg-sound-card";
		aml-audio-card,name = "AML-AUGESOUND";

		aml-audio-card,dai-link@0 {
			format = "dsp_a";
			mclk-fs = <0x200>;

			cpu {
				sound-dai = <0x3f>;
				dai-tdm-slot-tx-mask = <0x01 0x01 0x01 0x01 0x01 0x01 0x01 0x01>;
				dai-tdm-slot-rx-mask = <0x01 0x01 0x01 0x01 0x01 0x01 0x01 0x01>;
				dai-tdm-slot-num = <0x08>;
				dai-tdm-slot-width = <0x20>;
				system-clock-frequency = <0x1770000>;
				phandle = <0xa6>;
			};

			codec {
				sound-dai = <0x40 0x40>;
				phandle = <0xa7>;
			};
		};

		aml-audio-card,dai-link@1 {
			format = "i2s";
			mclk-fs = <0x100>;
			bitclock-master = <0x41>;
			frame-master = <0x41>;

			cpu {
				sound-dai = <0x41>;
				dai-tdm-slot-tx-mask = <0x01 0x01>;
				dai-tdm-slot-rx-mask = <0x01 0x01>;
				dai-tdm-slot-num = <0x02>;
				dai-tdm-slot-width = <0x20>;
				system-clock-frequency = <0xbb8000>;
			};

			codec {
				sound-dai = <0x42 0x40>;
			};
		};

		aml-audio-card,dai-link@2 {
			format = "i2s";
			mclk-fs = <0x100>;

			cpu {
				sound-dai = <0x43>;
				dai-tdm-slot-tx-mask = <0x01 0x01>;
				dai-tdm-slot-rx-mask = <0x01 0x01>;
				dai-tdm-slot-num = <0x02>;
				dai-tdm-slot-width = <0x20>;
				system-clock-frequency = <0xbb8000>;
			};

			codec {
				prefix-names = "5707_A\05707_B";
				sound-dai = <0x44 0x45 0x40>;
			};
		};

		aml-audio-card,dai-link@3 {
			mclk-fs = <0x100>;

			cpu {
				sound-dai = <0x46>;
			};

			codec {
				sound-dai = <0x40>;
			};
		};

		aml-audio-card,dai-link@4 {
			mclk-fs = <0x80>;

			cpu {
				sound-dai = <0x47>;
				system-clock-frequency = <0x5dc000>;
			};

			codec {
				sound-dai = <0x40>;
			};
		};

		aml-audio-card,dai-link@5 {
			mclk-fs = <0x100>;
			continuous-clock;
			suffix-name = "alsaPORT-loopback";

			cpu {
				sound-dai = <0x48>;
				system-clock-frequency = <0xbb8000>;
			};

			codec {
				sound-dai = <0x40>;
			};
		};
	};

	locker {
		compatible = "amlogic, audiolocker";
		clocks = <0x14 0x1e 0x14 0x1f 0x14 0x17 0x14 0x18 0x0d 0x0d 0x0d 0x0e>;
		clock-names = "lock_out\0lock_in\0out_src\0in_src\0out_calc\0in_ref";
		interrupts = <0x00 0x01 0x01>;
		interrupt-names = "irq";
		frequency = <0x2ebae40>;
		dividor = <0x31>;
		status = "okay";
		phandle = <0xa8>;
	};

	bt-dev {
		compatible = "amlogic, bt-dev";
		dev_name = "bt-dev";
		status = "okay";
		gpio_reset = <0x2c 0x44 0x00>;
	};

	wifi {
		compatible = "amlogic, aml_wifi";
		dev_name = "aml_wifi";
		status = "okay";
		interrupt_pin = <0x2c 0x35 0x00>;
		interrupts = <0x00 0x43 0x04>;
		irq_trigger_type = "GPIO_IRQ_LOW";
		power_on_pin2 = <0x2c 0x3f 0x00>;
		power_on_pin = <0x2c 0x36 0x00>;
		dhd_static_buf;
		pinctrl-names = "default";
		pinctrl-0 = <0x49>;
		pwm_config = <0x4a>;
	};

	wifi_pwm_conf {
		phandle = <0x4a>;

		pwm_channel1_conf {
			pwms = <0x30 0x00 0x774d 0x00>;
			duty-cycle = <0x3ba6>;
			times = <0x0a>;
		};

		pwm_channel2_conf {
			pwms = <0x30 0x02 0x7724 0x00>;
			duty-cycle = <0x3b92>;
			times = <0x0c>;
		};
	};

	emmc@ffe07000 {
		status = "disabled";
		compatible = "amlogic, meson-mmc-axg";
		reg = <0x00 0xffe07000 0x00 0x2000>;
		interrupts = <0x00 0xda 0x01>;
		pinctrl-names = "emmc_clk_cmd_pins\0emmc_all_pins";
		pinctrl-0 = <0x4b>;
		pinctrl-1 = <0x4c 0x4d>;
		clocks = <0x0d 0x31 0x0d 0x53 0x0d 0x02 0x0d 0x05 0x0a>;
		clock-names = "core\0clkin0\0clkin1\0clkin2\0xtal";
		bus-width = <0x08>;
		cap-sd-highspeed;
		cap-mmc-highspeed;
		mmc-ddr-1_8v;
		mmc-hs200-1_8v;
		max-frequency = <0xbebc200>;
		non-removable;
		disable-wp;
		phandle = <0xa9>;

		emmc {
			pinname = "emmc";
			ocr_avail = <0x200080>;
			caps = "MMC_CAP_8_BIT_DATA\0MMC_CAP_MMC_HIGHSPEED\0MMC_CAP_SD_HIGHSPEED\0MMC_CAP_NONREMOVABLE\0MMC_CAP_1_8V_DDR\0MMC_CAP_HW_RESET\0MMC_CAP_ERASE\0MMC_CAP_CMD23";
			caps2 = "MMC_CAP2_HS200\0MMC_CAP2_HS400";
			f_min = <0x61a80>;
			f_max = <0xbebc200>;
			max_req_size = <0x20000>;
			gpio_dat3 = <0x2c 0x0e 0x00>;
			hw_reset = <0x2c 0x14 0x00>;
			card_type = <0x01>;
		};
	};

	sdio@ffe05000 {
		status = "okay";
		compatible = "amlogic, meson-mmc-axg";
		reg = <0x00 0xffe05000 0x00 0x2000>;
		interrupts = <0x00 0xd9 0x04>;
		pinctrl-names = "sdio_clk_cmd_pins\0sdio_all_pins";
		pinctrl-0 = <0x4e>;
		pinctrl-1 = <0x4f>;
		clocks = <0x0d 0x30 0x0d 0x4f 0x0d 0x02 0x0d 0x05 0x0a>;
		clock-names = "core\0clkin0\0clkin1\0clkin2\0xtal";
		bus-width = <0x04>;
		cap-sd-highspeed;
		cap-mmc-highspeed;
		max-frequency = <0x5f5e100>;
		non-removable;
		disable-wp;
		phandle = <0xaa>;

		sdio {
			pinname = "sdio";
			ocr_avail = <0x200080>;
			caps = "MMC_CAP_4_BIT_DATA\0MMC_CAP_MMC_HIGHSPEED\0MMC_CAP_SD_HIGHSPEED\0MMC_CAP_NONREMOVABLE\0MMC_CAP_UHS_SDR12\0MMC_CAP_UHS_SDR25\0MMC_CAP_UHS_SDR50\0MMC_CAP_UHS_SDR104\0MMC_PM_KEEP_POWER\0MMC_CAP_SDIO_IRQ";
			f_min = <0x61a80>;
			f_max = <0xbebc200>;
			max_req_size = <0x20000>;
			card_type = <0x03>;
		};
	};

	partitions {
		parts = <0x0b>;
		part-0 = <0x50>;
		part-1 = <0x51>;
		part-2 = <0x52>;
		part-3 = <0x53>;
		part-4 = <0x54>;
		part-5 = <0x55>;
		part-6 = <0x56>;
		part-7 = <0x57>;
		part-8 = <0x58>;
		part-9 = <0x59>;
		part-10 = <0x5a>;
		phandle = <0xab>;

		logo {
			pname = "logo";
			size = <0x00 0x2000000>;
			mask = <0x01>;
			phandle = <0x50>;
		};

		recovery {
			pname = "recovery";
			size = <0x00 0x2000000>;
			mask = <0x01>;
			phandle = <0x51>;
		};

		rsv {
			pname = "rsv";
			size = <0x00 0x800000>;
			mask = <0x01>;
			phandle = <0x52>;
		};

		tee {
			pname = "tee";
			size = <0x00 0x800000>;
			mask = <0x01>;
			phandle = <0x53>;
		};

		crypt {
			pname = "crypt";
			size = <0x00 0x2000000>;
			mask = <0x01>;
			phandle = <0x54>;
		};

		misc {
			pname = "misc";
			size = <0x00 0x2000000>;
			mask = <0x01>;
			phandle = <0x55>;
		};

		instaboot {
			pname = "instaboot";
			size = <0x00 0x400000>;
			mask = <0x01>;
			phandle = <0x56>;
		};

		boot {
			pname = "boot";
			size = <0x00 0x2000000>;
			mask = <0x01>;
			phandle = <0x57>;
		};

		system {
			pname = "system";
			size = <0x00 0x80000000>;
			mask = <0x01>;
			phandle = <0x58>;
		};

		cache {
			pname = "cache";
			size = <0x00 0x20000000>;
			mask = <0x02>;
			phandle = <0x59>;
		};

		data {
			pname = "data";
			size = <0xffffffff 0xffffffff>;
			mask = <0x04>;
			phandle = <0x5a>;
		};
	};

	meson-fb {
		compatible = "amlogic, meson-axg";
		memory-region = <0x5b>;
		dev_name = "meson-fb";
		status = "okay";
		interrupts = <0x00 0x03 0x01 0x00 0x59 0x01>;
		interrupt-names = "viu-vsync\0rdma";
		mem_size = <0x300000 0x1800000 0x00>;
		display_mode_default = "1080p60hz";
		scale_mode = <0x00>;
		display_size_default = <0x300 0x400 0x300 0x800 0x20>;
		mem_alloc = <0x01>;
		logo_addr = "0x3e000000";
		pxp_mode = <0x00>;
	};

	ge2d {
		compatible = "amlogic, ge2d-axg";
		dev_name = "ge2d";
		status = "okay";
		interrupts = <0x00 0x96 0x01>;
		interrupt-names = "ge2d";
		clocks = <0x0d 0x6d 0x0d 0x37 0x0d 0x6e>;
		clock-names = "clk_vapb_0\0clk_ge2d\0clk_ge2d_gate";
		reg = <0x00 0xff940000 0x00 0x10000>;
	};

	adc_keypad {
		compatible = "amlogic, adc_keypad";
		status = "okay";
		key_name = "power\0vol-\0vol+\0wifi\0<<\0>>";
		key_num = <0x06>;
		io-channels = <0x5c 0x00>;
		io-channel-names = "key-chan-0";
		key_chan = <0x00 0x00 0x00 0x00 0x00 0x00>;
		key_code = <0x74 0x72 0x73 0x8b 0x69 0x6a>;
		key_val = <0x00 0x8f 0x10a 0x185 0x200 0x27b>;
		key_tolerance = <0x28 0x28 0x28 0x28 0x28 0x28>;
	};

	unifykey {
		compatible = "amlogic, unifykey";
		status = "ok";
		unifykey-num = <0x06>;
		unifykey-index-0 = <0x5d>;
		unifykey-index-1 = <0x5e>;
		unifykey-index-2 = <0x5f>;
		unifykey-index-3 = <0x60>;
		unifykey-index-4 = <0x61>;
		unifykey-index-5 = <0x62>;

		key_0 {
			key-name = "usid";
			key-device = "normal";
			key-permit = "read\0write\0del";
			phandle = <0x5d>;
		};

		key_1 {
			key-name = "mac";
			key-device = "normal";
			key-permit = "read\0write\0del";
			phandle = <0x5e>;
		};

		key_2 {
			key-name = "secure_boot_set";
			key-device = "efuse";
			key-permit = "write";
			phandle = <0x5f>;
		};

		key_3 {
			key-name = "mac_bt";
			key-device = "normal";
			key-permit = "read\0write\0del";
			key-type = "mac";
			phandle = <0x60>;
		};

		key_4 {
			key-name = "mac_wifi";
			key-device = "normal";
			key-permit = "read\0write\0del";
			key-type = "mac";
			phandle = <0x61>;
		};

		key_5 {
			key-name = "deviceid";
			key-device = "normal";
			key-permit = "read\0write\0del";
			phandle = <0x62>;
		};
	};

	__symbols__ {
		cpus = "/cpus";
		cluster0 = "/cpus/cpu-map/cluster0";
		CPU0 = "/cpus/cpu@0";
		CPU1 = "/cpus/cpu@1";
		CPU2 = "/cpus/cpu@2";
		CPU3 = "/cpus/cpu@3";
		CPU_SLEEP_0 = "/cpus/idle-states/cpu-sleep-0";
		gic = "/interrupt-controller@2c001000";
		mailbox = "/mhu@c883c400";
		scpi_dvfs = "/scpi_clocks/scpi_clocks@0";
		xtal = "/xtal-clk";
		dolby_fw = "/dolby_fw";
		wdt_ee = "/watchdog@0xffd0f0d0";
		pinctrl_aobus = "/pinctrl@ff800014";
		gpio_ao = "/pinctrl@ff800014/ao-bank@ff800014";
		remote_pins = "/pinctrl@ff800014/remote_pin";
		irblaster_pins = "/pinctrl@ff800014/irblaster_pin";
		ao_uart_pins = "/pinctrl@ff800014/ao_uart";
		ao_b_1_uart_pins = "/pinctrl@ff800014/ao_b_1_uart";
		ao_i2c_master = "/pinctrl@ff800014/ao_i2c";
		ao_i2c_master_pin1 = "/pinctrl@ff800014/ao_i2c_pin1";
		ao_i2c_master_pin2 = "/pinctrl@ff800014/ao_i2c_pin2";
		i2c_slave_pin = "/pinctrl@ff800014/s_i2c";
		jtag_apao_pins = "/pinctrl@ff800014/jtag_apao_pin";
		pinctrl_periphs = "/pinctrl@ff634480";
		gpio = "/pinctrl@ff634480/banks@ff634480";
		external_eth_pins = "/pinctrl@ff634480/external_eth_pins";
		ao_b_uart_pins = "/pinctrl@ff634480/ao_b_uart";
		a_uart_pins = "/pinctrl@ff634480/a_uart";
		b_uart_pins = "/pinctrl@ff634480/b_uart";
		a_i2c_master = "/pinctrl@ff634480/a_i2c";
		b_i2c_master = "/pinctrl@ff634480/b_i2c";
		b_i2c_master_pin1 = "/pinctrl@ff634480/b_i2c_pin1";
		c_i2c_master = "/pinctrl@ff634480/c_i2c";
		c_i2c_master_pin1 = "/pinctrl@ff634480/c_i2c_pin1";
		d_i2c_master = "/pinctrl@ff634480/d_i2c";
		d_i2c_master_pin1 = "/pinctrl@ff634480/d_i2c_pin1";
		d_i2c_master_pin2 = "/pinctrl@ff634480/d_i2c_pin2";
		spi0_pins = "/pinctrl@ff634480/spi0";
		spi1_a_pins = "/pinctrl@ff634480/spi1_a";
		spi1_x_pins = "/pinctrl@ff634480/spi1_x";
		nand_pulldown = "/pinctrl@ff634480/nand_pulldown";
		nand_pullup = "/pinctrl@ff634480/nand_pullup";
		all_nand_pins = "/pinctrl@ff634480/all_nand_pins";
		nand_cs_pins = "/pinctrl@ff634480/nand_cs";
		emmc_clk_cmd_pins = "/pinctrl@ff634480/emmc_clk_cmd_pins";
		emmc_conf_pull_up = "/pinctrl@ff634480/emmc_conf_pull_up";
		emmc_conf_pull_done = "/pinctrl@ff634480/emmc_conf_pull_done";
		sdio_clk_cmd_pins = "/pinctrl@ff634480/sdio_clk_cmd_pins";
		sdio_all_pins = "/pinctrl@ff634480/sdio_all_pins";
		wifi_32k_pins = "/pinctrl@ff634480/wifi_32k_pins";
		jtag_apee_pins = "/pinctrl@ff634480/jtag_apee_pin";
		tdmout_a = "/pinctrl@ff634480/tdmout_a";
		tdmout_a_data = "/pinctrl@ff634480/tdmout_a_data";
		tdmin_a = "/pinctrl@ff634480/tdmin_a";
		tdmb_mclk = "/pinctrl@ff634480/tdmb_mclk";
		tdmout_b = "/pinctrl@ff634480/tdmout_b";
		tdmin_b = "/pinctrl@ff634480/tdmin_b";
		tdmc_mclk = "/pinctrl@ff634480/tdmc_mclk";
		tdmout_c = "/pinctrl@ff634480/tdmout_c";
		tdmin_c = "/pinctrl@ff634480/tdmin_c";
		spdifout = "/pinctrl@ff634480/spidfout";
		spdifin = "/pinctrl@ff634480/spidfin";
		pdmin = "/pinctrl@ff634480/pdmin";
		bl_pwm_on_pins = "/pinctrl@ff634480/bl_pwm_on_pin";
		bl_pwm_off_pins = "/pinctrl@ff634480/bl_pwm_off_pin";
		cbus = "/soc/cbus@ffd00000";
		gpio_intc = "/soc/cbus@ffd00000/interrupt-controller@f080";
		i2c0 = "/soc/cbus@ffd00000/i2c@1f000";
		i2c1 = "/soc/cbus@ffd00000/i2c@1e000";
		tlv320adc3101_32 = "/soc/cbus@ffd00000/i2c@1e000/tlv320adc3101_32@32";
		tas5707_36 = "/soc/cbus@ffd00000/i2c@1e000/tas5707_36@36";
		tas5707_3a = "/soc/cbus@ffd00000/i2c@1e000/tas5707_3a@3a";
		i2c2 = "/soc/cbus@ffd00000/i2c@1d000";
		i2c3 = "/soc/cbus@ffd00000/i2c@1c000";
		spicc0 = "/soc/cbus@ffd00000/spi@13000";
		spicc1 = "/soc/cbus@ffd00000/spi@15000";
		aobus = "/soc/aobus@ff800000";
		aoclkc = "/soc/aobus@ff800000/clock-controller@0";
		i2c_AO = "/soc/aobus@ff800000/i2c@5000";
		aml_pca9557 = "/soc/aobus@ff800000/i2c@5000/aml_pca9557@0x1f";
		tlv320adc3101_30 = "/soc/aobus@ff800000/i2c@5000/tlv320adc3101_30@30";
		tlv320adc3101_34 = "/soc/aobus@ff800000/i2c@5000/tlv320adc3101_34@30";
		tlv320adc3101_36 = "/soc/aobus@ff800000/i2c@5000/tlv320adc3101_36@30";
		es7243_10 = "/soc/aobus@ff800000/i2c@5000/es7243_10@10";
		es7243_12 = "/soc/aobus@ff800000/i2c@5000/es7243_12@12";
		es7243_13 = "/soc/aobus@ff800000/i2c@5000/es7243_13@13";
		is31fl3236a = "/soc/aobus@ff800000/i2c@5000/is31f3236a@0x78";
		irblaster = "/soc/aobus@ff800000/meson-irblaster@c0";
		uart_AO = "/soc/aobus@ff800000/serial@3000";
		uart_AO_B = "/soc/aobus@ff800000/serial@4000";
		periphs = "/soc/periphs@ff634400";
		hiubus = "/soc/hiubus@ff63c000";
		clkc = "/soc/hiubus@ff63c000/clock-controller@0";
		audiobus = "/soc/audiobus@0xff642000";
		clkaudio = "/soc/audiobus@0xff642000/audio_clocks";
		aml_tdma = "/soc/audiobus@0xff642000/tdma";
		aml_tdmb = "/soc/audiobus@0xff642000/tdmb";
		aml_tdmc = "/soc/audiobus@0xff642000/tdmc";
		tdmlb = "/soc/audiobus@0xff642000/tdm@3";
		aml_spdif = "/soc/audiobus@0xff642000/spdif";
		aml_pdm = "/soc/audiobus@0xff642000/pdm";
		loopback = "/soc/audiobus@0xff642000/loopback@0";
		audioresample = "/soc/audiobus@0xff642000/resample";
		aml_pwrdet = "/soc/audiobus@0xff642000/pwrdet";
		pwm_ab = "/pwm@ffd1b000";
		pwm_cd = "/pwm@ffd1a000";
		pwm_aoab = "/pwm@ff807000";
		pwm_aocd = "/pwm@ff802000";
		remote = "/rc@0xff808040";
		custom_maps = "/custom_maps";
		map_0 = "/custom_maps/map_0";
		map_1 = "/custom_maps/map_1";
		map_2 = "/custom_maps/map_2";
		i2c_slave = "/i2c_slave@ff806000";
		saradc = "/saradc";
		efuse = "/efuse";
		efusekey = "/efusekey";
		key_0 = "/efusekey/key_0";
		key_1 = "/efusekey/key_1";
		key_2 = "/efusekey/key_2";
		key_3 = "/efusekey/key_3";
		audio_data = "/audio_data";
		defendkey = "/defendkey";
		bl_pwm_conf = "/bl_pwm_conf";
		secmon_reserved = "/reserved-memory/linux,secmon";
		secos_reserved = "/reserved-memory/linux,secos";
		fb_reserved = "/reserved-memory/linux,meson-fb";
		bootloader = "/mtd_nand/bootloader";
		nandnormal = "/mtd_nand/nandnormal";
		nand_partitions = "/mtd_nand/nand_partition";
		ethmac = "/ethernet@0xff3f0000";
		aml_sensor0 = "/aml-sensor@0";
		cpufreq_cool0 = "/aml-sensor@0/cpufreq_cool0";
		cpucore_cool0 = "/aml-sensor@0/cpucore_cool0";
		switch_on = "/thermal-zones/soc_thermal/trips/trip-point@0";
		control = "/thermal-zones/soc_thermal/trips/trip-point@1";
		hot = "/thermal-zones/soc_thermal/trips/trip-point@2";
		critical = "/thermal-zones/soc_thermal/trips/trip-point@3";
		dwc3 = "/dwc3@ff500000";
		usb2_phy = "/usb2phy@ffe09000";
		usb3_phy = "/usb3phy@ffe09080";
		pcie_A = "/pcieA@f9800000";
		pcie_B = "/pcieB@fa000000";
		uart_A = "/serial@ffd24000";
		uart_B = "/serial@ffd23000";
		dummy_codec = "/dummy";
		pdm_codec = "/dummy";
		tdmacpu = "/auge_sound/aml-audio-card,dai-link@0/cpu";
		tdmacodec = "/auge_sound/aml-audio-card,dai-link@0/codec";
		audiolocker = "/locker";
		wifi_pwm_conf = "/wifi_pwm_conf";
		sd_emmc_c = "/emmc@ffe07000";
		sd_emmc_b = "/sdio@ffe05000";
		partitions = "/partitions";
		logo = "/partitions/logo";
		recovery = "/partitions/recovery";
		rsv = "/partitions/rsv";
		tee = "/partitions/tee";
		crypt = "/partitions/crypt";
		misc = "/partitions/misc";
		instaboot = "/partitions/instaboot";
		boot = "/partitions/boot";
		system = "/partitions/system";
		cache = "/partitions/cache";
		data = "/partitions/data";
		keysn_0 = "/unifykey/key_0";
		keysn_1 = "/unifykey/key_1";
		keysn_2 = "/unifykey/key_2";
		keysn_3 = "/unifykey/key_3";
		keysn_4 = "/unifykey/key_4";
		keysn_5 = "/unifykey/key_5";
	};
};
